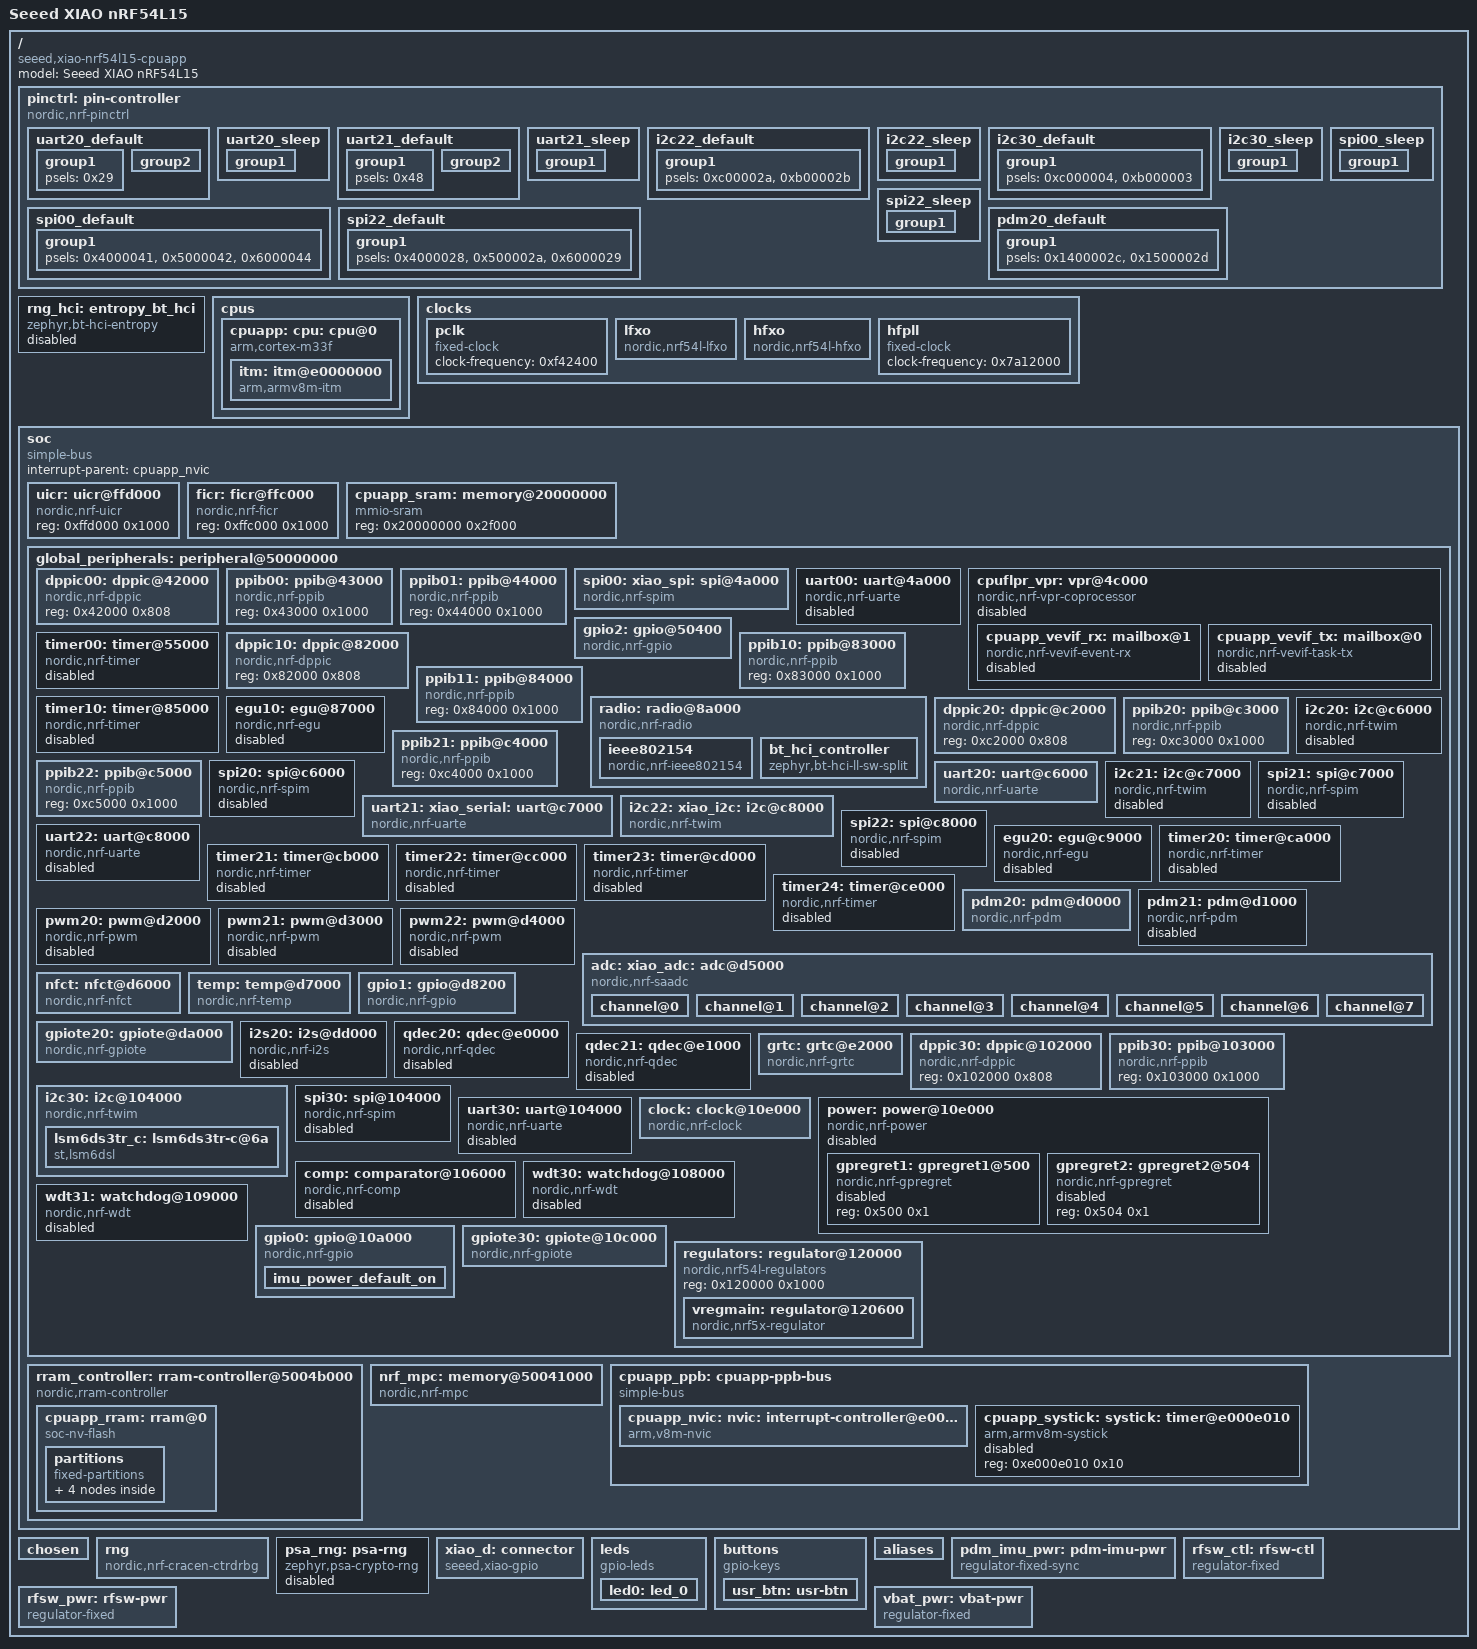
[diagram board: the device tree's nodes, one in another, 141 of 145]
/dts-v1/;

/* node '/' defined in framework-zephyr\dts\vendor\nordic\nrf_common.dtsi:24 */
/ {
	#address-cells = < 0x1 >;                  /* in framework-zephyr\dts\vendor\nordic\nrf54l_05_10_15.dtsi:19 */
	#size-cells = < 0x1 >;                     /* in framework-zephyr\dts\vendor\nordic\nrf54l_05_10_15.dtsi:20 */
	model = "Seeed XIAO nRF54L15";             /* in ..\platforms\Seeed Studio\zephyr\boards\arm\xiao_nrf54l15\xiao_nrf54l15_nrf54l15_cpuapp.dts:12 */
	compatible = "seeed,xiao-nrf54l15-cpuapp"; /* in ..\platforms\Seeed Studio\zephyr\boards\arm\xiao_nrf54l15\xiao_nrf54l15_nrf54l15_cpuapp.dts:13 */

	/* node '/pin-controller' defined in framework-zephyr\dts\vendor\nordic\nrf_common.dtsi:25 */
	pinctrl: pin-controller {
		compatible = "nordic,nrf-pinctrl"; /* in framework-zephyr\dts\vendor\nordic\nrf_common.dtsi:30 */

		/* node '/pin-controller/uart20_default' defined in ..\platforms\Seeed Studio\zephyr\boards\arm\xiao_nrf54l15\xiao_nrf54l15-pinctrl.dtsi:6 */
		uart20_default: uart20_default {
			phandle = < 0x6 >; /* in ..\platforms\Seeed Studio\zephyr\boards\arm\xiao_nrf54l15\xiao_nrf54l15_common.dtsi:39 */

			/* node '/pin-controller/uart20_default/group1' defined in ..\platforms\Seeed Studio\zephyr\boards\arm\xiao_nrf54l15\xiao_nrf54l15-pinctrl.dtsi:7 */
			group1 {
				psels = < 0x29 >; /* in ..\platforms\Seeed Studio\zephyr\boards\arm\xiao_nrf54l15\xiao_nrf54l15-pinctrl.dtsi:8 */
			};

			/* node '/pin-controller/uart20_default/group2' defined in ..\platforms\Seeed Studio\zephyr\boards\arm\xiao_nrf54l15\xiao_nrf54l15-pinctrl.dtsi:11 */
			group2 {
				psels = < 0x1000028 >; /* in ..\platforms\Seeed Studio\zephyr\boards\arm\xiao_nrf54l15\xiao_nrf54l15-pinctrl.dtsi:12 */
				bias-pull-up;          /* in ..\platforms\Seeed Studio\zephyr\boards\arm\xiao_nrf54l15\xiao_nrf54l15-pinctrl.dtsi:13 */
			};
		};

		/* node '/pin-controller/uart20_sleep' defined in ..\platforms\Seeed Studio\zephyr\boards\arm\xiao_nrf54l15\xiao_nrf54l15-pinctrl.dtsi:17 */
		uart20_sleep: uart20_sleep {
			phandle = < 0x7 >; /* in ..\platforms\Seeed Studio\zephyr\boards\arm\xiao_nrf54l15\xiao_nrf54l15_common.dtsi:40 */

			/* node '/pin-controller/uart20_sleep/group1' defined in ..\platforms\Seeed Studio\zephyr\boards\arm\xiao_nrf54l15\xiao_nrf54l15-pinctrl.dtsi:18 */
			group1 {
				psels = < 0x29 >,
				        < 0x1000028 >; /* in ..\platforms\Seeed Studio\zephyr\boards\arm\xiao_nrf54l15\xiao_nrf54l15-pinctrl.dtsi:19 */
				low-power-enable;      /* in ..\platforms\Seeed Studio\zephyr\boards\arm\xiao_nrf54l15\xiao_nrf54l15-pinctrl.dtsi:21 */
			};
		};

		/* node '/pin-controller/uart21_default' defined in ..\platforms\Seeed Studio\zephyr\boards\arm\xiao_nrf54l15\xiao_nrf54l15-pinctrl.dtsi:25 */
		uart21_default: uart21_default {
			phandle = < 0x8 >; /* in ..\platforms\Seeed Studio\zephyr\boards\arm\xiao_nrf54l15\xiao_nrf54l15_common.dtsi:46 */

			/* node '/pin-controller/uart21_default/group1' defined in ..\platforms\Seeed Studio\zephyr\boards\arm\xiao_nrf54l15\xiao_nrf54l15-pinctrl.dtsi:26 */
			group1 {
				psels = < 0x48 >; /* in ..\platforms\Seeed Studio\zephyr\boards\arm\xiao_nrf54l15\xiao_nrf54l15-pinctrl.dtsi:27 */
			};

			/* node '/pin-controller/uart21_default/group2' defined in ..\platforms\Seeed Studio\zephyr\boards\arm\xiao_nrf54l15\xiao_nrf54l15-pinctrl.dtsi:30 */
			group2 {
				psels = < 0x1000047 >; /* in ..\platforms\Seeed Studio\zephyr\boards\arm\xiao_nrf54l15\xiao_nrf54l15-pinctrl.dtsi:31 */
				bias-pull-up;          /* in ..\platforms\Seeed Studio\zephyr\boards\arm\xiao_nrf54l15\xiao_nrf54l15-pinctrl.dtsi:32 */
			};
		};

		/* node '/pin-controller/uart21_sleep' defined in ..\platforms\Seeed Studio\zephyr\boards\arm\xiao_nrf54l15\xiao_nrf54l15-pinctrl.dtsi:36 */
		uart21_sleep: uart21_sleep {
			phandle = < 0x9 >; /* in ..\platforms\Seeed Studio\zephyr\boards\arm\xiao_nrf54l15\xiao_nrf54l15_common.dtsi:47 */

			/* node '/pin-controller/uart21_sleep/group1' defined in ..\platforms\Seeed Studio\zephyr\boards\arm\xiao_nrf54l15\xiao_nrf54l15-pinctrl.dtsi:37 */
			group1 {
				psels = < 0x48 >,
				        < 0x1000047 >; /* in ..\platforms\Seeed Studio\zephyr\boards\arm\xiao_nrf54l15\xiao_nrf54l15-pinctrl.dtsi:38 */
				low-power-enable;      /* in ..\platforms\Seeed Studio\zephyr\boards\arm\xiao_nrf54l15\xiao_nrf54l15-pinctrl.dtsi:40 */
			};
		};

		/* node '/pin-controller/i2c22_default' defined in ..\platforms\Seeed Studio\zephyr\boards\arm\xiao_nrf54l15\xiao_nrf54l15-pinctrl.dtsi:44 */
		i2c22_default: i2c22_default {
			phandle = < 0xa >; /* in ..\platforms\Seeed Studio\zephyr\boards\arm\xiao_nrf54l15\xiao_nrf54l15_common.dtsi:52 */

			/* node '/pin-controller/i2c22_default/group1' defined in ..\platforms\Seeed Studio\zephyr\boards\arm\xiao_nrf54l15\xiao_nrf54l15-pinctrl.dtsi:45 */
			group1 {
				psels = < 0xc00002a >,
				        < 0xb00002b >; /* in ..\platforms\Seeed Studio\zephyr\boards\arm\xiao_nrf54l15\xiao_nrf54l15-pinctrl.dtsi:46 */
			};
		};

		/* node '/pin-controller/i2c22_sleep' defined in ..\platforms\Seeed Studio\zephyr\boards\arm\xiao_nrf54l15\xiao_nrf54l15-pinctrl.dtsi:51 */
		i2c22_sleep: i2c22_sleep {
			phandle = < 0xb >; /* in ..\platforms\Seeed Studio\zephyr\boards\arm\xiao_nrf54l15\xiao_nrf54l15_common.dtsi:53 */

			/* node '/pin-controller/i2c22_sleep/group1' defined in ..\platforms\Seeed Studio\zephyr\boards\arm\xiao_nrf54l15\xiao_nrf54l15-pinctrl.dtsi:52 */
			group1 {
				psels = < 0xc00002a >,
				        < 0xb00002b >; /* in ..\platforms\Seeed Studio\zephyr\boards\arm\xiao_nrf54l15\xiao_nrf54l15-pinctrl.dtsi:53 */
				low-power-enable;      /* in ..\platforms\Seeed Studio\zephyr\boards\arm\xiao_nrf54l15\xiao_nrf54l15-pinctrl.dtsi:55 */
			};
		};

		/* node '/pin-controller/i2c30_default' defined in ..\platforms\Seeed Studio\zephyr\boards\arm\xiao_nrf54l15\xiao_nrf54l15-pinctrl.dtsi:59 */
		i2c30_default: i2c30_default {
			phandle = < 0x12 >; /* in ..\platforms\Seeed Studio\zephyr\boards\arm\xiao_nrf54l15\xiao_nrf54l15_common.dtsi:59 */

			/* node '/pin-controller/i2c30_default/group1' defined in ..\platforms\Seeed Studio\zephyr\boards\arm\xiao_nrf54l15\xiao_nrf54l15-pinctrl.dtsi:60 */
			group1 {
				psels = < 0xc000004 >,
				        < 0xb000003 >; /* in ..\platforms\Seeed Studio\zephyr\boards\arm\xiao_nrf54l15\xiao_nrf54l15-pinctrl.dtsi:61 */
			};
		};

		/* node '/pin-controller/i2c30_sleep' defined in ..\platforms\Seeed Studio\zephyr\boards\arm\xiao_nrf54l15\xiao_nrf54l15-pinctrl.dtsi:66 */
		i2c30_sleep: i2c30_sleep {
			phandle = < 0x13 >; /* in ..\platforms\Seeed Studio\zephyr\boards\arm\xiao_nrf54l15\xiao_nrf54l15_common.dtsi:60 */

			/* node '/pin-controller/i2c30_sleep/group1' defined in ..\platforms\Seeed Studio\zephyr\boards\arm\xiao_nrf54l15\xiao_nrf54l15-pinctrl.dtsi:67 */
			group1 {
				psels = < 0xc000004 >,
				        < 0xb000003 >; /* in ..\platforms\Seeed Studio\zephyr\boards\arm\xiao_nrf54l15\xiao_nrf54l15-pinctrl.dtsi:68 */
				low-power-enable;      /* in ..\platforms\Seeed Studio\zephyr\boards\arm\xiao_nrf54l15\xiao_nrf54l15-pinctrl.dtsi:70 */
			};
		};

		/* node '/pin-controller/spi00_default' defined in ..\platforms\Seeed Studio\zephyr\boards\arm\xiao_nrf54l15\xiao_nrf54l15-pinctrl.dtsi:74 */
		spi00_default: spi00_default {
			phandle = < 0x3 >; /* in ..\platforms\Seeed Studio\zephyr\boards\arm\xiao_nrf54l15\xiao_nrf54l15_common.dtsi:66 */

			/* node '/pin-controller/spi00_default/group1' defined in ..\platforms\Seeed Studio\zephyr\boards\arm\xiao_nrf54l15\xiao_nrf54l15-pinctrl.dtsi:75 */
			group1 {
				psels = < 0x4000041 >,
				        < 0x5000042 >,
				        < 0x6000044 >; /* in ..\platforms\Seeed Studio\zephyr\boards\arm\xiao_nrf54l15\xiao_nrf54l15-pinctrl.dtsi:76 */
			};
		};

		/* node '/pin-controller/spi00_sleep' defined in ..\platforms\Seeed Studio\zephyr\boards\arm\xiao_nrf54l15\xiao_nrf54l15-pinctrl.dtsi:82 */
		spi00_sleep: spi00_sleep {
			phandle = < 0x4 >; /* in ..\platforms\Seeed Studio\zephyr\boards\arm\xiao_nrf54l15\xiao_nrf54l15_common.dtsi:67 */

			/* node '/pin-controller/spi00_sleep/group1' defined in ..\platforms\Seeed Studio\zephyr\boards\arm\xiao_nrf54l15\xiao_nrf54l15-pinctrl.dtsi:83 */
			group1 {
				psels = < 0x4000041 >,
				        < 0x5000042 >,
				        < 0x6000044 >; /* in ..\platforms\Seeed Studio\zephyr\boards\arm\xiao_nrf54l15\xiao_nrf54l15-pinctrl.dtsi:84 */
				low-power-enable;      /* in ..\platforms\Seeed Studio\zephyr\boards\arm\xiao_nrf54l15\xiao_nrf54l15-pinctrl.dtsi:87 */
			};
		};

		/* node '/pin-controller/spi22_default' defined in ..\platforms\Seeed Studio\zephyr\boards\arm\xiao_nrf54l15\xiao_nrf54l15-pinctrl.dtsi:91 */
		spi22_default: spi22_default {
			phandle = < 0xc >; /* in ..\platforms\Seeed Studio\zephyr\boards\arm\xiao_nrf54l15\xiao_nrf54l15_common.dtsi:72 */

			/* node '/pin-controller/spi22_default/group1' defined in ..\platforms\Seeed Studio\zephyr\boards\arm\xiao_nrf54l15\xiao_nrf54l15-pinctrl.dtsi:92 */
			group1 {
				psels = < 0x4000028 >,
				        < 0x500002a >,
				        < 0x6000029 >; /* in ..\platforms\Seeed Studio\zephyr\boards\arm\xiao_nrf54l15\xiao_nrf54l15-pinctrl.dtsi:93 */
			};
		};

		/* node '/pin-controller/spi22_sleep' defined in ..\platforms\Seeed Studio\zephyr\boards\arm\xiao_nrf54l15\xiao_nrf54l15-pinctrl.dtsi:99 */
		spi22_sleep: spi22_sleep {
			phandle = < 0xd >; /* in ..\platforms\Seeed Studio\zephyr\boards\arm\xiao_nrf54l15\xiao_nrf54l15_common.dtsi:73 */

			/* node '/pin-controller/spi22_sleep/group1' defined in ..\platforms\Seeed Studio\zephyr\boards\arm\xiao_nrf54l15\xiao_nrf54l15-pinctrl.dtsi:100 */
			group1 {
				psels = < 0x4000028 >,
				        < 0x500002a >,
				        < 0x6000029 >; /* in ..\platforms\Seeed Studio\zephyr\boards\arm\xiao_nrf54l15\xiao_nrf54l15-pinctrl.dtsi:101 */
				low-power-enable;      /* in ..\platforms\Seeed Studio\zephyr\boards\arm\xiao_nrf54l15\xiao_nrf54l15-pinctrl.dtsi:104 */
			};
		};

		/* node '/pin-controller/pdm20_default' defined in ..\platforms\Seeed Studio\zephyr\boards\arm\xiao_nrf54l15\xiao_nrf54l15-pinctrl.dtsi:108 */
		pdm20_default: pdm20_default {
			phandle = < 0xe >; /* in ..\platforms\Seeed Studio\zephyr\boards\arm\xiao_nrf54l15\xiao_nrf54l15_common.dtsi:78 */

			/* node '/pin-controller/pdm20_default/group1' defined in ..\platforms\Seeed Studio\zephyr\boards\arm\xiao_nrf54l15\xiao_nrf54l15-pinctrl.dtsi:109 */
			group1 {
				psels = < 0x1400002c >,
				        < 0x1500002d >; /* in ..\platforms\Seeed Studio\zephyr\boards\arm\xiao_nrf54l15\xiao_nrf54l15-pinctrl.dtsi:110 */
			};
		};
	};

	/* node '/entropy_bt_hci' defined in framework-zephyr\dts\vendor\nordic\nrf_common.dtsi:33 */
	rng_hci: entropy_bt_hci {
		compatible = "zephyr,bt-hci-entropy"; /* in framework-zephyr\dts\vendor\nordic\nrf_common.dtsi:34 */
		status = "disabled";                  /* in framework-zephyr\dts\vendor\nordic\nrf_common.dtsi:35 */
	};

	/* node '/cpus' defined in framework-zephyr\dts\vendor\nordic\nrf54l_05_10_15.dtsi:22 */
	cpus {
		#address-cells = < 0x1 >; /* in framework-zephyr\dts\vendor\nordic\nrf54l_05_10_15.dtsi:23 */
		#size-cells = < 0x0 >;    /* in framework-zephyr\dts\vendor\nordic\nrf54l_05_10_15.dtsi:24 */

		/* node '/cpus/cpu@0' defined in framework-zephyr\dts\vendor\nordic\nrf54l_05_10_15.dtsi:26 */
		cpuapp: cpu: cpu@0 {
			compatible = "arm,cortex-m33f"; /* in framework-zephyr\dts\vendor\nordic\nrf54l_05_10_15.dtsi:27 */
			reg = < 0x0 >;                  /* in framework-zephyr\dts\vendor\nordic\nrf54l_05_10_15.dtsi:28 */
			device_type = "cpu";            /* in framework-zephyr\dts\vendor\nordic\nrf54l_05_10_15.dtsi:29 */
			clocks = < &hfpll >;            /* in framework-zephyr\dts\vendor\nordic\nrf54l_05_10_15.dtsi:30 */
			#address-cells = < 0x1 >;       /* in framework-zephyr\dts\vendor\nordic\nrf54l_05_10_15.dtsi:31 */
			#size-cells = < 0x1 >;          /* in framework-zephyr\dts\vendor\nordic\nrf54l_05_10_15.dtsi:32 */

			/* node '/cpus/cpu@0/itm@e0000000' defined in framework-zephyr\dts\vendor\nordic\nrf54l_05_10_15.dtsi:34 */
			itm: itm@e0000000 {
				compatible = "arm,armv8m-itm";     /* in framework-zephyr\dts\vendor\nordic\nrf54l_05_10_15.dtsi:35 */
				reg = < 0xe0000000 0x1000 >;       /* in framework-zephyr\dts\vendor\nordic\nrf54l_05_10_15.dtsi:36 */
				swo-ref-frequency = < 0x7a12000 >; /* in framework-zephyr\dts\vendor\nordic\nrf54l_05_10_15.dtsi:37 */
			};
		};
	};

	/* node '/clocks' defined in framework-zephyr\dts\vendor\nordic\nrf54l_05_10_15.dtsi:51 */
	clocks {

		/* node '/clocks/pclk' defined in framework-zephyr\dts\vendor\nordic\nrf54l_05_10_15.dtsi:52 */
		pclk: pclk {
			compatible = "fixed-clock";     /* in framework-zephyr\dts\vendor\nordic\nrf54l_05_10_15.dtsi:53 */
			#clock-cells = < 0x0 >;         /* in framework-zephyr\dts\vendor\nordic\nrf54l_05_10_15.dtsi:54 */
			clock-frequency = < 0xf42400 >; /* in framework-zephyr\dts\vendor\nordic\nrf54l_05_10_15.dtsi:55 */
			phandle = < 0x11 >;             /* in framework-zephyr\dts\vendor\nordic\nrf54l_05_10_15.dtsi:569 */
		};

		/* node '/clocks/lfxo' defined in framework-zephyr\dts\vendor\nordic\nrf54l_05_10_15.dtsi:58 */
		lfxo: lfxo {
			compatible = "nordic,nrf54l-lfxo";        /* in framework-zephyr\dts\vendor\nordic\nrf54l_05_10_15.dtsi:59 */
			#clock-cells = < 0x0 >;                   /* in framework-zephyr\dts\vendor\nordic\nrf54l_05_10_15.dtsi:60 */
			clock-frequency = < 0x8000 >;             /* in framework-zephyr\dts\vendor\nordic\nrf54l_05_10_15.dtsi:61 */
			load-capacitors = "internal";             /* in ..\platforms\Seeed Studio\zephyr\boards\arm\xiao_nrf54l15\xiao_nrf54l15_nrf54l15_cpuapp.dts:146 */
			load-capacitance-femtofarad = < 0x3e80 >; /* in ..\platforms\Seeed Studio\zephyr\boards\arm\xiao_nrf54l15\xiao_nrf54l15_nrf54l15_cpuapp.dts:147 */
			status = "okay";                          /* in ..\platforms\Seeed Studio\zephyr\boards\arm\xiao_nrf54l15\xiao_nrf54l15_nrf54l15_cpuapp.dts:148 */
			phandle = < 0x10 >;                       /* in framework-zephyr\dts\vendor\nordic\nrf54l_05_10_15.dtsi:569 */
		};

		/* node '/clocks/hfxo' defined in framework-zephyr\dts\vendor\nordic\nrf54l_05_10_15.dtsi:64 */
		hfxo: hfxo {
			compatible = "nordic,nrf54l-hfxo";        /* in framework-zephyr\dts\vendor\nordic\nrf54l_05_10_15.dtsi:65 */
			#clock-cells = < 0x0 >;                   /* in framework-zephyr\dts\vendor\nordic\nrf54l_05_10_15.dtsi:66 */
			clock-frequency = < 0x1e84800 >;          /* in framework-zephyr\dts\vendor\nordic\nrf54l_05_10_15.dtsi:67 */
			startup-time-us = < 0x672 >;              /* in framework-zephyr\dts\vendor\nordic\nrf54l_05_10_15.dtsi:68 */
			load-capacitors = "internal";             /* in ..\platforms\Seeed Studio\zephyr\boards\arm\xiao_nrf54l15\xiao_nrf54l15_nrf54l15_cpuapp.dts:152 */
			load-capacitance-femtofarad = < 0x3e80 >; /* in ..\platforms\Seeed Studio\zephyr\boards\arm\xiao_nrf54l15\xiao_nrf54l15_nrf54l15_cpuapp.dts:153 */
			status = "okay";                          /* in ..\platforms\Seeed Studio\zephyr\boards\arm\xiao_nrf54l15\xiao_nrf54l15_nrf54l15_cpuapp.dts:154 */
			phandle = < 0x5 >;                        /* in framework-zephyr\dts\vendor\nordic\nrf54l_05_10_15.dtsi:226 */
		};

		/* node '/clocks/hfpll' defined in framework-zephyr\dts\vendor\nordic\nrf54l_05_10_15.dtsi:71 */
		hfpll: hfpll {
			compatible = "fixed-clock";      /* in framework-zephyr\dts\vendor\nordic\nrf54l_05_10_15.dtsi:72 */
			#clock-cells = < 0x0 >;          /* in framework-zephyr\dts\vendor\nordic\nrf54l_05_10_15.dtsi:73 */
			clock-frequency = < 0x7a12000 >; /* in framework-zephyr\dts\vendor\nordic\nrf54l_05_10_15.dtsi:74 */
			phandle = < 0x1 >;               /* in framework-zephyr\dts\vendor\nordic\nrf54l_05_10_15.dtsi:30 */
		};
	};

	/* node '/soc' defined in framework-zephyr\dts\vendor\nordic\nrf54l_05_10_15.dtsi:78 */
	soc {
		#address-cells = < 0x1 >;            /* in framework-zephyr\dts\vendor\nordic\nrf54l_05_10_15.dtsi:79 */
		#size-cells = < 0x1 >;               /* in framework-zephyr\dts\vendor\nordic\nrf54l_05_10_15.dtsi:80 */
		compatible = "simple-bus";           /* in framework-zephyr\dts\arm\nordic\nrf54l_05_10_15_cpuapp.dtsi:23 */
		interrupt-parent = < &cpuapp_nvic >; /* in framework-zephyr\dts\arm\nordic\nrf54l_05_10_15_cpuapp.dtsi:24 */
		ranges;                              /* in framework-zephyr\dts\arm\nordic\nrf54l_05_10_15_cpuapp.dtsi:25 */

		/* node '/soc/uicr@ffd000' defined in framework-zephyr\dts\vendor\nordic\nrf54l_05_10_15.dtsi:85 */
		uicr: uicr@ffd000 {
			compatible = "nordic,nrf-uicr"; /* in framework-zephyr\dts\vendor\nordic\nrf54l_05_10_15.dtsi:86 */
			reg = < 0xffd000 0x1000 >;      /* in framework-zephyr\dts\vendor\nordic\nrf54l_05_10_15.dtsi:87 */
		};

		/* node '/soc/ficr@ffc000' defined in framework-zephyr\dts\vendor\nordic\nrf54l_05_10_15.dtsi:90 */
		ficr: ficr@ffc000 {
			compatible = "nordic,nrf-ficr"; /* in framework-zephyr\dts\vendor\nordic\nrf54l_05_10_15.dtsi:91 */
			reg = < 0xffc000 0x1000 >;      /* in framework-zephyr\dts\vendor\nordic\nrf54l_05_10_15.dtsi:92 */
			#nordic,ficr-cells = < 0x1 >;   /* in framework-zephyr\dts\vendor\nordic\nrf54l_05_10_15.dtsi:93 */
		};

		/* node '/soc/memory@20000000' defined in framework-zephyr\dts\vendor\nordic\nrf54l_05_10_15.dtsi:96 */
		cpuapp_sram: memory@20000000 {
			compatible = "mmio-sram";            /* in framework-zephyr\dts\vendor\nordic\nrf54l_05_10_15.dtsi:97 */
			#address-cells = < 0x1 >;            /* in framework-zephyr\dts\vendor\nordic\nrf54l_05_10_15.dtsi:98 */
			#size-cells = < 0x1 >;               /* in framework-zephyr\dts\vendor\nordic\nrf54l_05_10_15.dtsi:99 */
			reg = < 0x20000000 0x2f000 >;        /* in framework-zephyr\dts\vendor\nordic\nrf54l15.dtsi:10 */
			ranges = < 0x0 0x20000000 0x2f000 >; /* in framework-zephyr\dts\vendor\nordic\nrf54l15.dtsi:11 */
			status = "okay";                     /* in ..\platforms\Seeed Studio\zephyr\boards\arm\xiao_nrf54l15\xiao_nrf54l15_nrf54l15_cpuapp.dts:61 */
		};

		/* node '/soc/peripheral@50000000' defined in framework-zephyr\dts\vendor\nordic\nrf54l_05_10_15.dtsi:108 */
		global_peripherals: peripheral@50000000 {
			#address-cells = < 0x1 >;               /* in framework-zephyr\dts\vendor\nordic\nrf54l_05_10_15.dtsi:109 */
			#size-cells = < 0x1 >;                  /* in framework-zephyr\dts\vendor\nordic\nrf54l_05_10_15.dtsi:110 */
			ranges = < 0x0 0x50000000 0x10000000 >; /* in framework-zephyr\dts\vendor\nordic\nrf54l_05_10_15.dtsi:111 */

			/* node '/soc/peripheral@50000000/dppic@42000' defined in framework-zephyr\dts\vendor\nordic\nrf54l_05_10_15.dtsi:114 */
			dppic00: dppic@42000 {
				compatible = "nordic,nrf-dppic"; /* in framework-zephyr\dts\vendor\nordic\nrf54l_05_10_15.dtsi:115 */
				reg = < 0x42000 0x808 >;         /* in framework-zephyr\dts\vendor\nordic\nrf54l_05_10_15.dtsi:116 */
				status = "okay";                 /* in framework-zephyr\dts\arm\nordic\nrf54l_05_10_15_cpuapp.dtsi:95 */
			};

			/* node '/soc/peripheral@50000000/ppib@43000' defined in framework-zephyr\dts\vendor\nordic\nrf54l_05_10_15.dtsi:120 */
			ppib00: ppib@43000 {
				compatible = "nordic,nrf-ppib"; /* in framework-zephyr\dts\vendor\nordic\nrf54l_05_10_15.dtsi:121 */
				reg = < 0x43000 0x1000 >;       /* in framework-zephyr\dts\vendor\nordic\nrf54l_05_10_15.dtsi:122 */
				status = "okay";                /* in framework-zephyr\dts\arm\nordic\nrf54l_05_10_15_cpuapp.dtsi:111 */
			};

			/* node '/soc/peripheral@50000000/ppib@44000' defined in framework-zephyr\dts\vendor\nordic\nrf54l_05_10_15.dtsi:126 */
			ppib01: ppib@44000 {
				compatible = "nordic,nrf-ppib"; /* in framework-zephyr\dts\vendor\nordic\nrf54l_05_10_15.dtsi:127 */
				reg = < 0x44000 0x1000 >;       /* in framework-zephyr\dts\vendor\nordic\nrf54l_05_10_15.dtsi:128 */
				status = "okay";                /* in framework-zephyr\dts\arm\nordic\nrf54l_05_10_15_cpuapp.dtsi:115 */
			};

			/* node '/soc/peripheral@50000000/spi@4a000' defined in framework-zephyr\dts\vendor\nordic\nrf54l_05_10_15.dtsi:132 */
			spi00: xiao_spi: spi@4a000 {
				compatible = "nordic,nrf-spim"; /* in framework-zephyr\dts\vendor\nordic\nrf54l_05_10_15.dtsi:139 */
				#address-cells = < 0x1 >;       /* in framework-zephyr\dts\vendor\nordic\nrf54l_05_10_15.dtsi:140 */
				#size-cells = < 0x0 >;          /* in framework-zephyr\dts\vendor\nordic\nrf54l_05_10_15.dtsi:141 */
				reg = < 0x4a000 0x1000 >;       /* in framework-zephyr\dts\vendor\nordic\nrf54l_05_10_15.dtsi:142 */
				interrupts = < 0x4a 0x1 >;      /* in framework-zephyr\dts\vendor\nordic\nrf54l_05_10_15.dtsi:143 */
				max-frequency = < 0x1e84800 >;  /* in framework-zephyr\dts\vendor\nordic\nrf54l_05_10_15.dtsi:144 */
				easydma-maxcnt-bits = < 0x10 >; /* in framework-zephyr\dts\vendor\nordic\nrf54l_05_10_15.dtsi:145 */
				rx-delay-supported;             /* in framework-zephyr\dts\vendor\nordic\nrf54l_05_10_15.dtsi:146 */
				rx-delay = < 0x1 >;             /* in framework-zephyr\dts\vendor\nordic\nrf54l_05_10_15.dtsi:147 */
				pinctrl-0 = < &spi00_default >; /* in ..\platforms\Seeed Studio\zephyr\boards\arm\xiao_nrf54l15\xiao_nrf54l15_common.dtsi:66 */
				pinctrl-1 = < &spi00_sleep >;   /* in ..\platforms\Seeed Studio\zephyr\boards\arm\xiao_nrf54l15\xiao_nrf54l15_common.dtsi:67 */
				pinctrl-names = "default",
				                "sleep";        /* in ..\platforms\Seeed Studio\zephyr\boards\arm\xiao_nrf54l15\xiao_nrf54l15_common.dtsi:68 */
				status = "okay";                /* in ..\platforms\Seeed Studio\zephyr\boards\arm\xiao_nrf54l15\xiao_nrf54l15_nrf54l15_cpuapp.dts:99 */
				clocks = < &hfpll >;            /* in H:/nrf54l15/spi/zephyr/xiao_nrf54l15_nrf54l15_cpuapp.overlay:14 */
			};

			/* node '/soc/peripheral@50000000/uart@4a000' defined in framework-zephyr\dts\vendor\nordic\nrf54l_05_10_15.dtsi:151 */
			uart00: uart@4a000 {
				compatible = "nordic,nrf-uarte"; /* in framework-zephyr\dts\vendor\nordic\nrf54l_05_10_15.dtsi:152 */
				reg = < 0x4a000 0x1000 >;        /* in framework-zephyr\dts\vendor\nordic\nrf54l_05_10_15.dtsi:153 */
				interrupts = < 0x4a 0x1 >;       /* in framework-zephyr\dts\vendor\nordic\nrf54l_05_10_15.dtsi:154 */
				clocks = < &hfpll >;             /* in framework-zephyr\dts\vendor\nordic\nrf54l_05_10_15.dtsi:155 */
				status = "disabled";             /* in framework-zephyr\dts\vendor\nordic\nrf54l_05_10_15.dtsi:156 */
				endtx-stoptx-supported;          /* in framework-zephyr\dts\vendor\nordic\nrf54l_05_10_15.dtsi:157 */
				frame-timeout-supported;         /* in framework-zephyr\dts\vendor\nordic\nrf54l_05_10_15.dtsi:158 */
			};

			/* node '/soc/peripheral@50000000/vpr@4c000' defined in framework-zephyr\dts\vendor\nordic\nrf54l_05_10_15.dtsi:161 */
			cpuflpr_vpr: vpr@4c000 {
				compatible = "nordic,nrf-vpr-coprocessor"; /* in framework-zephyr\dts\vendor\nordic\nrf54l_05_10_15.dtsi:162 */
				reg = < 0x4c000 0x1000 >;                  /* in framework-zephyr\dts\vendor\nordic\nrf54l_05_10_15.dtsi:163 */
				ranges = < 0x0 0x4c000 0x1000 >;           /* in framework-zephyr\dts\vendor\nordic\nrf54l_05_10_15.dtsi:164 */
				#address-cells = < 0x1 >;                  /* in framework-zephyr\dts\vendor\nordic\nrf54l_05_10_15.dtsi:165 */
				#size-cells = < 0x1 >;                     /* in framework-zephyr\dts\vendor\nordic\nrf54l_05_10_15.dtsi:166 */
				status = "disabled";                       /* in framework-zephyr\dts\vendor\nordic\nrf54l_05_10_15.dtsi:167 */
				enable-secure;                             /* in framework-zephyr\dts\vendor\nordic\nrf54l_05_10_15.dtsi:168 */

				/* node '/soc/peripheral@50000000/vpr@4c000/mailbox@1' defined in framework-zephyr\dts\arm\nordic\nrf54l_05_10_15_cpuapp.dtsi:44 */
				cpuapp_vevif_rx: mailbox@1 {
					compatible = "nordic,nrf-vevif-event-rx"; /* in framework-zephyr\dts\arm\nordic\nrf54l_05_10_15_cpuapp.dtsi:45 */
					reg = < 0x1 0x1000 >;                     /* in framework-zephyr\dts\arm\nordic\nrf54l_05_10_15_cpuapp.dtsi:46 */
					status = "disabled";                      /* in framework-zephyr\dts\arm\nordic\nrf54l_05_10_15_cpuapp.dtsi:47 */
					interrupts = < 0x4c 0x1 >;                /* in framework-zephyr\dts\arm\nordic\nrf54l_05_10_15_cpuapp.dtsi:48 */
					#mbox-cells = < 0x1 >;                    /* in framework-zephyr\dts\arm\nordic\nrf54l_05_10_15_cpuapp.dtsi:49 */
					nordic,events = < 0x1 >;                  /* in framework-zephyr\dts\arm\nordic\nrf54l_05_10_15_cpuapp.dtsi:50 */
					nordic,events-mask = < 0x100000 >;        /* in framework-zephyr\dts\arm\nordic\nrf54l_05_10_15_cpuapp.dtsi:51 */
				};

				/* node '/soc/peripheral@50000000/vpr@4c000/mailbox@0' defined in framework-zephyr\dts\arm\nordic\nrf54l_05_10_15_cpuapp.dtsi:54 */
				cpuapp_vevif_tx: mailbox@0 {
					compatible = "nordic,nrf-vevif-task-tx"; /* in framework-zephyr\dts\arm\nordic\nrf54l_05_10_15_cpuapp.dtsi:55 */
					reg = < 0x0 0x1000 >;                    /* in framework-zephyr\dts\arm\nordic\nrf54l_05_10_15_cpuapp.dtsi:56 */
					#mbox-cells = < 0x1 >;                   /* in framework-zephyr\dts\arm\nordic\nrf54l_05_10_15_cpuapp.dtsi:57 */
					nordic,tasks = < 0x7 >;                  /* in framework-zephyr\dts\arm\nordic\nrf54l_05_10_15_cpuapp.dtsi:58 */
					nordic,tasks-mask = < 0x7f0000 >;        /* in framework-zephyr\dts\arm\nordic\nrf54l_05_10_15_cpuapp.dtsi:59 */
					status = "disabled";                     /* in framework-zephyr\dts\arm\nordic\nrf54l_05_10_15_cpuapp.dtsi:60 */
				};
			};

			/* node '/soc/peripheral@50000000/gpio@50400' defined in framework-zephyr\dts\vendor\nordic\nrf54l_05_10_15.dtsi:180 */
			gpio2: gpio@50400 {
				compatible = "nordic,nrf-gpio"; /* in framework-zephyr\dts\vendor\nordic\nrf54l_05_10_15.dtsi:181 */
				gpio-controller;                /* in framework-zephyr\dts\vendor\nordic\nrf54l_05_10_15.dtsi:182 */
				reg = < 0x50400 0x300 >;        /* in framework-zephyr\dts\vendor\nordic\nrf54l_05_10_15.dtsi:183 */
				#gpio-cells = < 0x2 >;          /* in framework-zephyr\dts\vendor\nordic\nrf54l_05_10_15.dtsi:184 */
				ngpios = < 0xb >;               /* in framework-zephyr\dts\vendor\nordic\nrf54l_05_10_15.dtsi:185 */
				port = < 0x2 >;                 /* in framework-zephyr\dts\vendor\nordic\nrf54l_05_10_15.dtsi:187 */
				status = "okay";                /* in ..\platforms\Seeed Studio\zephyr\boards\arm\xiao_nrf54l15\xiao_nrf54l15_nrf54l15_cpuapp.dts:125 */
				phandle = < 0x17 >;             /* in ..\platforms\Seeed Studio\zephyr\boards\arm\xiao_nrf54l15\seeed_xiao_connector.dtsi:11 */
			};

			/* node '/soc/peripheral@50000000/timer@55000' defined in framework-zephyr\dts\vendor\nordic\nrf54l_05_10_15.dtsi:190 */
			timer00: timer@55000 {
				compatible = "nordic,nrf-timer"; /* in framework-zephyr\dts\vendor\nordic\nrf54l_05_10_15.dtsi:191 */
				status = "disabled";             /* in framework-zephyr\dts\vendor\nordic\nrf54l_05_10_15.dtsi:192 */
				reg = < 0x55000 0x1000 >;        /* in framework-zephyr\dts\vendor\nordic\nrf54l_05_10_15.dtsi:193 */
				cc-num = < 0x6 >;                /* in framework-zephyr\dts\vendor\nordic\nrf54l_05_10_15.dtsi:194 */
				max-bit-width = < 0x20 >;        /* in framework-zephyr\dts\vendor\nordic\nrf54l_05_10_15.dtsi:195 */
				interrupts = < 0x55 0x1 >;       /* in framework-zephyr\dts\vendor\nordic\nrf54l_05_10_15.dtsi:196 */
				clocks = < &hfpll >;             /* in framework-zephyr\dts\vendor\nordic\nrf54l_05_10_15.dtsi:197 */
				prescaler = < 0x0 >;             /* in framework-zephyr\dts\vendor\nordic\nrf54l_05_10_15.dtsi:198 */
			};

			/* node '/soc/peripheral@50000000/dppic@82000' defined in framework-zephyr\dts\vendor\nordic\nrf54l_05_10_15.dtsi:201 */
			dppic10: dppic@82000 {
				compatible = "nordic,nrf-dppic"; /* in framework-zephyr\dts\vendor\nordic\nrf54l_05_10_15.dtsi:202 */
				reg = < 0x82000 0x808 >;         /* in framework-zephyr\dts\vendor\nordic\nrf54l_05_10_15.dtsi:203 */
				status = "okay";                 /* in framework-zephyr\dts\arm\nordic\nrf54l_05_10_15_cpuapp.dtsi:99 */
			};

			/* node '/soc/peripheral@50000000/ppib@83000' defined in framework-zephyr\dts\vendor\nordic\nrf54l_05_10_15.dtsi:207 */
			ppib10: ppib@83000 {
				compatible = "nordic,nrf-ppib"; /* in framework-zephyr\dts\vendor\nordic\nrf54l_05_10_15.dtsi:208 */
				reg = < 0x83000 0x1000 >;       /* in framework-zephyr\dts\vendor\nordic\nrf54l_05_10_15.dtsi:209 */
				status = "okay";                /* in framework-zephyr\dts\arm\nordic\nrf54l_05_10_15_cpuapp.dtsi:119 */
			};

			/* node '/soc/peripheral@50000000/ppib@84000' defined in framework-zephyr\dts\vendor\nordic\nrf54l_05_10_15.dtsi:213 */
			ppib11: ppib@84000 {
				compatible = "nordic,nrf-ppib"; /* in framework-zephyr\dts\vendor\nordic\nrf54l_05_10_15.dtsi:214 */
				reg = < 0x84000 0x1000 >;       /* in framework-zephyr\dts\vendor\nordic\nrf54l_05_10_15.dtsi:215 */
				status = "okay";                /* in framework-zephyr\dts\arm\nordic\nrf54l_05_10_15_cpuapp.dtsi:123 */
			};

			/* node '/soc/peripheral@50000000/timer@85000' defined in framework-zephyr\dts\vendor\nordic\nrf54l_05_10_15.dtsi:219 */
			timer10: timer@85000 {
				compatible = "nordic,nrf-timer"; /* in framework-zephyr\dts\vendor\nordic\nrf54l_05_10_15.dtsi:220 */
				status = "disabled";             /* in framework-zephyr\dts\vendor\nordic\nrf54l_05_10_15.dtsi:221 */
				reg = < 0x85000 0x1000 >;        /* in framework-zephyr\dts\vendor\nordic\nrf54l_05_10_15.dtsi:222 */
				cc-num = < 0x8 >;                /* in framework-zephyr\dts\vendor\nordic\nrf54l_05_10_15.dtsi:223 */
				max-bit-width = < 0x20 >;        /* in framework-zephyr\dts\vendor\nordic\nrf54l_05_10_15.dtsi:224 */
				interrupts = < 0x85 0x1 >;       /* in framework-zephyr\dts\vendor\nordic\nrf54l_05_10_15.dtsi:225 */
				clocks = < &hfxo >;              /* in framework-zephyr\dts\vendor\nordic\nrf54l_05_10_15.dtsi:226 */
				prescaler = < 0x0 >;             /* in framework-zephyr\dts\vendor\nordic\nrf54l_05_10_15.dtsi:227 */
			};

			/* node '/soc/peripheral@50000000/egu@87000' defined in framework-zephyr\dts\vendor\nordic\nrf54l_05_10_15.dtsi:230 */
			egu10: egu@87000 {
				compatible = "nordic,nrf-egu"; /* in framework-zephyr\dts\vendor\nordic\nrf54l_05_10_15.dtsi:231 */
				reg = < 0x87000 0x1000 >;      /* in framework-zephyr\dts\vendor\nordic\nrf54l_05_10_15.dtsi:232 */
				interrupts = < 0x87 0x1 >;     /* in framework-zephyr\dts\vendor\nordic\nrf54l_05_10_15.dtsi:233 */
				status = "disabled";           /* in framework-zephyr\dts\vendor\nordic\nrf54l_05_10_15.dtsi:234 */
			};

			/* node '/soc/peripheral@50000000/radio@8a000' defined in framework-zephyr\dts\vendor\nordic\nrf54l_05_10_15.dtsi:237 */
			radio: radio@8a000 {
				compatible = "nordic,nrf-radio"; /* in framework-zephyr\dts\vendor\nordic\nrf54l_05_10_15.dtsi:238 */
				reg = < 0x8a000 0x1000 >;        /* in framework-zephyr\dts\vendor\nordic\nrf54l_05_10_15.dtsi:239 */
				interrupts = < 0x8a 0x1 >;       /* in framework-zephyr\dts\vendor\nordic\nrf54l_05_10_15.dtsi:240 */
				dfe-supported;                   /* in framework-zephyr\dts\vendor\nordic\nrf54l_05_10_15.dtsi:242 */
				ieee802154-supported;            /* in framework-zephyr\dts\vendor\nordic\nrf54l_05_10_15.dtsi:243 */
				ble-2mbps-supported;             /* in framework-zephyr\dts\vendor\nordic\nrf54l_05_10_15.dtsi:244 */
				ble-coded-phy-supported;         /* in framework-zephyr\dts\vendor\nordic\nrf54l_05_10_15.dtsi:245 */
				cs-supported;                    /* in framework-zephyr\dts\vendor\nordic\nrf54l_05_10_15.dtsi:246 */
				status = "okay";                 /* in ..\platforms\Seeed Studio\zephyr\boards\arm\xiao_nrf54l15\xiao_nrf54l15_nrf54l15_cpuapp.dts:167 */

				/* node '/soc/peripheral@50000000/radio@8a000/ieee802154' defined in framework-zephyr\dts\vendor\nordic\nrf54l_05_10_15.dtsi:248 */
				ieee802154: ieee802154 {
					compatible = "nordic,nrf-ieee802154"; /* in framework-zephyr\dts\vendor\nordic\nrf54l_05_10_15.dtsi:249 */
					status = "okay";                      /* in ..\platforms\Seeed Studio\zephyr\boards\arm\xiao_nrf54l15\xiao_nrf54l15_nrf54l15_cpuapp.dts:159 */
				};

				/* node '/soc/peripheral@50000000/radio@8a000/bt_hci_controller' defined in framework-zephyr\dts\vendor\nordic\nrf54l_05_10_15.dtsi:256 */
				bt_hci_controller: bt_hci_controller {
					compatible = "zephyr,bt-hci-ll-sw-split"; /* in framework-zephyr\dts\vendor\nordic\nrf54l_05_10_15.dtsi:257 */
					status = "okay";                          /* in framework-zephyr\dts\arm\nordic\nrf54l_05_10_15_cpuapp.dtsi:40 */
				};
			};

			/* node '/soc/peripheral@50000000/dppic@c2000' defined in framework-zephyr\dts\vendor\nordic\nrf54l_05_10_15.dtsi:262 */
			dppic20: dppic@c2000 {
				compatible = "nordic,nrf-dppic"; /* in framework-zephyr\dts\vendor\nordic\nrf54l_05_10_15.dtsi:263 */
				reg = < 0xc2000 0x808 >;         /* in framework-zephyr\dts\vendor\nordic\nrf54l_05_10_15.dtsi:264 */
				status = "okay";                 /* in framework-zephyr\dts\arm\nordic\nrf54l_05_10_15_cpuapp.dtsi:103 */
			};

			/* node '/soc/peripheral@50000000/ppib@c3000' defined in framework-zephyr\dts\vendor\nordic\nrf54l_05_10_15.dtsi:268 */
			ppib20: ppib@c3000 {
				compatible = "nordic,nrf-ppib"; /* in framework-zephyr\dts\vendor\nordic\nrf54l_05_10_15.dtsi:269 */
				reg = < 0xc3000 0x1000 >;       /* in framework-zephyr\dts\vendor\nordic\nrf54l_05_10_15.dtsi:270 */
				status = "okay";                /* in framework-zephyr\dts\arm\nordic\nrf54l_05_10_15_cpuapp.dtsi:127 */
			};

			/* node '/soc/peripheral@50000000/ppib@c4000' defined in framework-zephyr\dts\vendor\nordic\nrf54l_05_10_15.dtsi:274 */
			ppib21: ppib@c4000 {
				compatible = "nordic,nrf-ppib"; /* in framework-zephyr\dts\vendor\nordic\nrf54l_05_10_15.dtsi:275 */
				reg = < 0xc4000 0x1000 >;       /* in framework-zephyr\dts\vendor\nordic\nrf54l_05_10_15.dtsi:276 */
				status = "okay";                /* in framework-zephyr\dts\arm\nordic\nrf54l_05_10_15_cpuapp.dtsi:131 */
			};

			/* node '/soc/peripheral@50000000/ppib@c5000' defined in framework-zephyr\dts\vendor\nordic\nrf54l_05_10_15.dtsi:280 */
			ppib22: ppib@c5000 {
				compatible = "nordic,nrf-ppib"; /* in framework-zephyr\dts\vendor\nordic\nrf54l_05_10_15.dtsi:281 */
				reg = < 0xc5000 0x1000 >;       /* in framework-zephyr\dts\vendor\nordic\nrf54l_05_10_15.dtsi:282 */
				status = "okay";                /* in framework-zephyr\dts\arm\nordic\nrf54l_05_10_15_cpuapp.dtsi:135 */
			};

			/* node '/soc/peripheral@50000000/i2c@c6000' defined in framework-zephyr\dts\vendor\nordic\nrf54l_05_10_15.dtsi:286 */
			i2c20: i2c@c6000 {
				compatible = "nordic,nrf-twim"; /* in framework-zephyr\dts\vendor\nordic\nrf54l_05_10_15.dtsi:287 */
				#address-cells = < 0x1 >;       /* in framework-zephyr\dts\vendor\nordic\nrf54l_05_10_15.dtsi:288 */
				#size-cells = < 0x0 >;          /* in framework-zephyr\dts\vendor\nordic\nrf54l_05_10_15.dtsi:289 */
				reg = < 0xc6000 0x1000 >;       /* in framework-zephyr\dts\vendor\nordic\nrf54l_05_10_15.dtsi:290 */
				interrupts = < 0xc6 0x1 >;      /* in framework-zephyr\dts\vendor\nordic\nrf54l_05_10_15.dtsi:291 */
				easydma-maxcnt-bits = < 0x10 >; /* in framework-zephyr\dts\vendor\nordic\nrf54l_05_10_15.dtsi:292 */
				status = "disabled";            /* in framework-zephyr\dts\vendor\nordic\nrf54l_05_10_15.dtsi:293 */
				zephyr,pm-device-runtime-auto;  /* in framework-zephyr\dts\vendor\nordic\nrf54l_05_10_15.dtsi:294 */
			};

			/* node '/soc/peripheral@50000000/spi@c6000' defined in framework-zephyr\dts\vendor\nordic\nrf54l_05_10_15.dtsi:297 */
			spi20: spi@c6000 {
				compatible = "nordic,nrf-spim"; /* in framework-zephyr\dts\vendor\nordic\nrf54l_05_10_15.dtsi:304 */
				#address-cells = < 0x1 >;       /* in framework-zephyr\dts\vendor\nordic\nrf54l_05_10_15.dtsi:305 */
				#size-cells = < 0x0 >;          /* in framework-zephyr\dts\vendor\nordic\nrf54l_05_10_15.dtsi:306 */
				reg = < 0xc6000 0x1000 >;       /* in framework-zephyr\dts\vendor\nordic\nrf54l_05_10_15.dtsi:307 */
				interrupts = < 0xc6 0x1 >;      /* in framework-zephyr\dts\vendor\nordic\nrf54l_05_10_15.dtsi:308 */
				max-frequency = < 0x7a1200 >;   /* in framework-zephyr\dts\vendor\nordic\nrf54l_05_10_15.dtsi:309 */
				easydma-maxcnt-bits = < 0x10 >; /* in framework-zephyr\dts\vendor\nordic\nrf54l_05_10_15.dtsi:310 */
				rx-delay-supported;             /* in framework-zephyr\dts\vendor\nordic\nrf54l_05_10_15.dtsi:311 */
				rx-delay = < 0x1 >;             /* in framework-zephyr\dts\vendor\nordic\nrf54l_05_10_15.dtsi:312 */
				status = "disabled";            /* in framework-zephyr\dts\vendor\nordic\nrf54l_05_10_15.dtsi:313 */
			};

			/* node '/soc/peripheral@50000000/uart@c6000' defined in framework-zephyr\dts\vendor\nordic\nrf54l_05_10_15.dtsi:316 */
			uart20: uart@c6000 {
				compatible = "nordic,nrf-uarte"; /* in framework-zephyr\dts\vendor\nordic\nrf54l_05_10_15.dtsi:317 */
				reg = < 0xc6000 0x1000 >;        /* in framework-zephyr\dts\vendor\nordic\nrf54l_05_10_15.dtsi:318 */
				interrupts = < 0xc6 0x1 >;       /* in framework-zephyr\dts\vendor\nordic\nrf54l_05_10_15.dtsi:319 */
				endtx-stoptx-supported;          /* in framework-zephyr\dts\vendor\nordic\nrf54l_05_10_15.dtsi:321 */
				frame-timeout-supported;         /* in framework-zephyr\dts\vendor\nordic\nrf54l_05_10_15.dtsi:322 */
				current-speed = < 0x1c200 >;     /* in ..\platforms\Seeed Studio\zephyr\boards\arm\xiao_nrf54l15\xiao_nrf54l15_common.dtsi:38 */
				pinctrl-0 = < &uart20_default >; /* in ..\platforms\Seeed Studio\zephyr\boards\arm\xiao_nrf54l15\xiao_nrf54l15_common.dtsi:39 */
				pinctrl-1 = < &uart20_sleep >;   /* in ..\platforms\Seeed Studio\zephyr\boards\arm\xiao_nrf54l15\xiao_nrf54l15_common.dtsi:40 */
				pinctrl-names = "default",
				                "sleep";         /* in ..\platforms\Seeed Studio\zephyr\boards\arm\xiao_nrf54l15\xiao_nrf54l15_common.dtsi:41 */
				status = "okay";                 /* in ..\platforms\Seeed Studio\zephyr\boards\arm\xiao_nrf54l15\xiao_nrf54l15_nrf54l15_cpuapp.dts:76 */
			};

			/* node '/soc/peripheral@50000000/i2c@c7000' defined in framework-zephyr\dts\vendor\nordic\nrf54l_05_10_15.dtsi:325 */
			i2c21: i2c@c7000 {
				compatible = "nordic,nrf-twim"; /* in framework-zephyr\dts\vendor\nordic\nrf54l_05_10_15.dtsi:326 */
				#address-cells = < 0x1 >;       /* in framework-zephyr\dts\vendor\nordic\nrf54l_05_10_15.dtsi:327 */
				#size-cells = < 0x0 >;          /* in framework-zephyr\dts\vendor\nordic\nrf54l_05_10_15.dtsi:328 */
				reg = < 0xc7000 0x1000 >;       /* in framework-zephyr\dts\vendor\nordic\nrf54l_05_10_15.dtsi:329 */
				interrupts = < 0xc7 0x1 >;      /* in framework-zephyr\dts\vendor\nordic\nrf54l_05_10_15.dtsi:330 */
				easydma-maxcnt-bits = < 0x10 >; /* in framework-zephyr\dts\vendor\nordic\nrf54l_05_10_15.dtsi:331 */
				status = "disabled";            /* in framework-zephyr\dts\vendor\nordic\nrf54l_05_10_15.dtsi:332 */
				zephyr,pm-device-runtime-auto;  /* in framework-zephyr\dts\vendor\nordic\nrf54l_05_10_15.dtsi:333 */
			};

			/* node '/soc/peripheral@50000000/spi@c7000' defined in framework-zephyr\dts\vendor\nordic\nrf54l_05_10_15.dtsi:336 */
			spi21: spi@c7000 {
				compatible = "nordic,nrf-spim"; /* in framework-zephyr\dts\vendor\nordic\nrf54l_05_10_15.dtsi:343 */
				#address-cells = < 0x1 >;       /* in framework-zephyr\dts\vendor\nordic\nrf54l_05_10_15.dtsi:344 */
				#size-cells = < 0x0 >;          /* in framework-zephyr\dts\vendor\nordic\nrf54l_05_10_15.dtsi:345 */
				reg = < 0xc7000 0x1000 >;       /* in framework-zephyr\dts\vendor\nordic\nrf54l_05_10_15.dtsi:346 */
				interrupts = < 0xc7 0x1 >;      /* in framework-zephyr\dts\vendor\nordic\nrf54l_05_10_15.dtsi:347 */
				max-frequency = < 0x7a1200 >;   /* in framework-zephyr\dts\vendor\nordic\nrf54l_05_10_15.dtsi:348 */
				easydma-maxcnt-bits = < 0x10 >; /* in framework-zephyr\dts\vendor\nordic\nrf54l_05_10_15.dtsi:349 */
				rx-delay-supported;             /* in framework-zephyr\dts\vendor\nordic\nrf54l_05_10_15.dtsi:350 */
				rx-delay = < 0x1 >;             /* in framework-zephyr\dts\vendor\nordic\nrf54l_05_10_15.dtsi:351 */
				status = "disabled";            /* in framework-zephyr\dts\vendor\nordic\nrf54l_05_10_15.dtsi:352 */
			};

			/* node '/soc/peripheral@50000000/uart@c7000' defined in framework-zephyr\dts\vendor\nordic\nrf54l_05_10_15.dtsi:355 */
			uart21: xiao_serial: uart@c7000 {
				compatible = "nordic,nrf-uarte"; /* in framework-zephyr\dts\vendor\nordic\nrf54l_05_10_15.dtsi:356 */
				reg = < 0xc7000 0x1000 >;        /* in framework-zephyr\dts\vendor\nordic\nrf54l_05_10_15.dtsi:357 */
				interrupts = < 0xc7 0x1 >;       /* in framework-zephyr\dts\vendor\nordic\nrf54l_05_10_15.dtsi:358 */
				endtx-stoptx-supported;          /* in framework-zephyr\dts\vendor\nordic\nrf54l_05_10_15.dtsi:360 */
				frame-timeout-supported;         /* in framework-zephyr\dts\vendor\nordic\nrf54l_05_10_15.dtsi:361 */
				current-speed = < 0x1c200 >;     /* in ..\platforms\Seeed Studio\zephyr\boards\arm\xiao_nrf54l15\xiao_nrf54l15_common.dtsi:45 */
				pinctrl-0 = < &uart21_default >; /* in ..\platforms\Seeed Studio\zephyr\boards\arm\xiao_nrf54l15\xiao_nrf54l15_common.dtsi:46 */
				pinctrl-1 = < &uart21_sleep >;   /* in ..\platforms\Seeed Studio\zephyr\boards\arm\xiao_nrf54l15\xiao_nrf54l15_common.dtsi:47 */
				pinctrl-names = "default",
				                "sleep";         /* in ..\platforms\Seeed Studio\zephyr\boards\arm\xiao_nrf54l15\xiao_nrf54l15_common.dtsi:48 */
				status = "okay";                 /* in ..\platforms\Seeed Studio\zephyr\boards\arm\xiao_nrf54l15\xiao_nrf54l15_nrf54l15_cpuapp.dts:80 */
			};

			/* node '/soc/peripheral@50000000/i2c@c8000' defined in framework-zephyr\dts\vendor\nordic\nrf54l_05_10_15.dtsi:364 */
			i2c22: xiao_i2c: i2c@c8000 {
				compatible = "nordic,nrf-twim"; /* in framework-zephyr\dts\vendor\nordic\nrf54l_05_10_15.dtsi:365 */
				#address-cells = < 0x1 >;       /* in framework-zephyr\dts\vendor\nordic\nrf54l_05_10_15.dtsi:366 */
				#size-cells = < 0x0 >;          /* in framework-zephyr\dts\vendor\nordic\nrf54l_05_10_15.dtsi:367 */
				reg = < 0xc8000 0x1000 >;       /* in framework-zephyr\dts\vendor\nordic\nrf54l_05_10_15.dtsi:368 */
				interrupts = < 0xc8 0x1 >;      /* in framework-zephyr\dts\vendor\nordic\nrf54l_05_10_15.dtsi:369 */
				easydma-maxcnt-bits = < 0x10 >; /* in framework-zephyr\dts\vendor\nordic\nrf54l_05_10_15.dtsi:370 */
				zephyr,pm-device-runtime-auto;  /* in framework-zephyr\dts\vendor\nordic\nrf54l_05_10_15.dtsi:372 */
				pinctrl-0 = < &i2c22_default >; /* in ..\platforms\Seeed Studio\zephyr\boards\arm\xiao_nrf54l15\xiao_nrf54l15_common.dtsi:52 */
				pinctrl-1 = < &i2c22_sleep >;   /* in ..\platforms\Seeed Studio\zephyr\boards\arm\xiao_nrf54l15\xiao_nrf54l15_common.dtsi:53 */
				pinctrl-names = "default",
				                "sleep";        /* in ..\platforms\Seeed Studio\zephyr\boards\arm\xiao_nrf54l15\xiao_nrf54l15_common.dtsi:54 */
				clock-frequency = < 0x61a80 >;  /* in ..\platforms\Seeed Studio\zephyr\boards\arm\xiao_nrf54l15\xiao_nrf54l15_common.dtsi:55 */
				status = "okay";                /* in ..\platforms\Seeed Studio\zephyr\boards\arm\xiao_nrf54l15\xiao_nrf54l15_nrf54l15_cpuapp.dts:84 */
			};

			/* node '/soc/peripheral@50000000/spi@c8000' defined in framework-zephyr\dts\vendor\nordic\nrf54l_05_10_15.dtsi:375 */
			spi22: spi@c8000 {
				compatible = "nordic,nrf-spim"; /* in framework-zephyr\dts\vendor\nordic\nrf54l_05_10_15.dtsi:382 */
				#address-cells = < 0x1 >;       /* in framework-zephyr\dts\vendor\nordic\nrf54l_05_10_15.dtsi:383 */
				#size-cells = < 0x0 >;          /* in framework-zephyr\dts\vendor\nordic\nrf54l_05_10_15.dtsi:384 */
				reg = < 0xc8000 0x1000 >;       /* in framework-zephyr\dts\vendor\nordic\nrf54l_05_10_15.dtsi:385 */
				interrupts = < 0xc8 0x1 >;      /* in framework-zephyr\dts\vendor\nordic\nrf54l_05_10_15.dtsi:386 */
				max-frequency = < 0x7a1200 >;   /* in framework-zephyr\dts\vendor\nordic\nrf54l_05_10_15.dtsi:387 */
				easydma-maxcnt-bits = < 0x10 >; /* in framework-zephyr\dts\vendor\nordic\nrf54l_05_10_15.dtsi:388 */
				rx-delay-supported;             /* in framework-zephyr\dts\vendor\nordic\nrf54l_05_10_15.dtsi:389 */
				rx-delay = < 0x1 >;             /* in framework-zephyr\dts\vendor\nordic\nrf54l_05_10_15.dtsi:390 */
				status = "disabled";            /* in framework-zephyr\dts\vendor\nordic\nrf54l_05_10_15.dtsi:391 */
				pinctrl-0 = < &spi22_default >; /* in ..\platforms\Seeed Studio\zephyr\boards\arm\xiao_nrf54l15\xiao_nrf54l15_common.dtsi:72 */
				pinctrl-1 = < &spi22_sleep >;   /* in ..\platforms\Seeed Studio\zephyr\boards\arm\xiao_nrf54l15\xiao_nrf54l15_common.dtsi:73 */
				pinctrl-names = "default",
				                "sleep";        /* in ..\platforms\Seeed Studio\zephyr\boards\arm\xiao_nrf54l15\xiao_nrf54l15_common.dtsi:74 */
			};

			/* node '/soc/peripheral@50000000/uart@c8000' defined in framework-zephyr\dts\vendor\nordic\nrf54l_05_10_15.dtsi:394 */
			uart22: uart@c8000 {
				compatible = "nordic,nrf-uarte"; /* in framework-zephyr\dts\vendor\nordic\nrf54l_05_10_15.dtsi:395 */
				reg = < 0xc8000 0x1000 >;        /* in framework-zephyr\dts\vendor\nordic\nrf54l_05_10_15.dtsi:396 */
				interrupts = < 0xc8 0x1 >;       /* in framework-zephyr\dts\vendor\nordic\nrf54l_05_10_15.dtsi:397 */
				status = "disabled";             /* in framework-zephyr\dts\vendor\nordic\nrf54l_05_10_15.dtsi:398 */
				endtx-stoptx-supported;          /* in framework-zephyr\dts\vendor\nordic\nrf54l_05_10_15.dtsi:399 */
				frame-timeout-supported;         /* in framework-zephyr\dts\vendor\nordic\nrf54l_05_10_15.dtsi:400 */
			};

			/* node '/soc/peripheral@50000000/egu@c9000' defined in framework-zephyr\dts\vendor\nordic\nrf54l_05_10_15.dtsi:403 */
			egu20: egu@c9000 {
				compatible = "nordic,nrf-egu"; /* in framework-zephyr\dts\vendor\nordic\nrf54l_05_10_15.dtsi:404 */
				reg = < 0xc9000 0x1000 >;      /* in framework-zephyr\dts\vendor\nordic\nrf54l_05_10_15.dtsi:405 */
				interrupts = < 0xc9 0x1 >;     /* in framework-zephyr\dts\vendor\nordic\nrf54l_05_10_15.dtsi:406 */
				status = "disabled";           /* in framework-zephyr\dts\vendor\nordic\nrf54l_05_10_15.dtsi:407 */
			};

			/* node '/soc/peripheral@50000000/timer@ca000' defined in framework-zephyr\dts\vendor\nordic\nrf54l_05_10_15.dtsi:410 */
			timer20: timer@ca000 {
				compatible = "nordic,nrf-timer"; /* in framework-zephyr\dts\vendor\nordic\nrf54l_05_10_15.dtsi:411 */
				status = "disabled";             /* in framework-zephyr\dts\vendor\nordic\nrf54l_05_10_15.dtsi:412 */
				reg = < 0xca000 0x1000 >;        /* in framework-zephyr\dts\vendor\nordic\nrf54l_05_10_15.dtsi:413 */
				cc-num = < 0x6 >;                /* in framework-zephyr\dts\vendor\nordic\nrf54l_05_10_15.dtsi:414 */
				max-bit-width = < 0x20 >;        /* in framework-zephyr\dts\vendor\nordic\nrf54l_05_10_15.dtsi:415 */
				interrupts = < 0xca 0x1 >;       /* in framework-zephyr\dts\vendor\nordic\nrf54l_05_10_15.dtsi:416 */
				prescaler = < 0x0 >;             /* in framework-zephyr\dts\vendor\nordic\nrf54l_05_10_15.dtsi:417 */
			};

			/* node '/soc/peripheral@50000000/timer@cb000' defined in framework-zephyr\dts\vendor\nordic\nrf54l_05_10_15.dtsi:420 */
			timer21: timer@cb000 {
				compatible = "nordic,nrf-timer"; /* in framework-zephyr\dts\vendor\nordic\nrf54l_05_10_15.dtsi:421 */
				status = "disabled";             /* in framework-zephyr\dts\vendor\nordic\nrf54l_05_10_15.dtsi:422 */
				reg = < 0xcb000 0x1000 >;        /* in framework-zephyr\dts\vendor\nordic\nrf54l_05_10_15.dtsi:423 */
				cc-num = < 0x6 >;                /* in framework-zephyr\dts\vendor\nordic\nrf54l_05_10_15.dtsi:424 */
				max-bit-width = < 0x20 >;        /* in framework-zephyr\dts\vendor\nordic\nrf54l_05_10_15.dtsi:425 */
				interrupts = < 0xcb 0x1 >;       /* in framework-zephyr\dts\vendor\nordic\nrf54l_05_10_15.dtsi:426 */
				prescaler = < 0x0 >;             /* in framework-zephyr\dts\vendor\nordic\nrf54l_05_10_15.dtsi:427 */
			};

			/* node '/soc/peripheral@50000000/timer@cc000' defined in framework-zephyr\dts\vendor\nordic\nrf54l_05_10_15.dtsi:430 */
			timer22: timer@cc000 {
				compatible = "nordic,nrf-timer"; /* in framework-zephyr\dts\vendor\nordic\nrf54l_05_10_15.dtsi:431 */
				status = "disabled";             /* in framework-zephyr\dts\vendor\nordic\nrf54l_05_10_15.dtsi:432 */
				reg = < 0xcc000 0x1000 >;        /* in framework-zephyr\dts\vendor\nordic\nrf54l_05_10_15.dtsi:433 */
				cc-num = < 0x6 >;                /* in framework-zephyr\dts\vendor\nordic\nrf54l_05_10_15.dtsi:434 */
				max-bit-width = < 0x20 >;        /* in framework-zephyr\dts\vendor\nordic\nrf54l_05_10_15.dtsi:435 */
				interrupts = < 0xcc 0x1 >;       /* in framework-zephyr\dts\vendor\nordic\nrf54l_05_10_15.dtsi:436 */
				prescaler = < 0x0 >;             /* in framework-zephyr\dts\vendor\nordic\nrf54l_05_10_15.dtsi:437 */
			};

			/* node '/soc/peripheral@50000000/timer@cd000' defined in framework-zephyr\dts\vendor\nordic\nrf54l_05_10_15.dtsi:440 */
			timer23: timer@cd000 {
				compatible = "nordic,nrf-timer"; /* in framework-zephyr\dts\vendor\nordic\nrf54l_05_10_15.dtsi:441 */
				status = "disabled";             /* in framework-zephyr\dts\vendor\nordic\nrf54l_05_10_15.dtsi:442 */
				reg = < 0xcd000 0x1000 >;        /* in framework-zephyr\dts\vendor\nordic\nrf54l_05_10_15.dtsi:443 */
				cc-num = < 0x6 >;                /* in framework-zephyr\dts\vendor\nordic\nrf54l_05_10_15.dtsi:444 */
				max-bit-width = < 0x20 >;        /* in framework-zephyr\dts\vendor\nordic\nrf54l_05_10_15.dtsi:445 */
				interrupts = < 0xcd 0x1 >;       /* in framework-zephyr\dts\vendor\nordic\nrf54l_05_10_15.dtsi:446 */
				prescaler = < 0x0 >;             /* in framework-zephyr\dts\vendor\nordic\nrf54l_05_10_15.dtsi:447 */
			};

			/* node '/soc/peripheral@50000000/timer@ce000' defined in framework-zephyr\dts\vendor\nordic\nrf54l_05_10_15.dtsi:450 */
			timer24: timer@ce000 {
				compatible = "nordic,nrf-timer"; /* in framework-zephyr\dts\vendor\nordic\nrf54l_05_10_15.dtsi:451 */
				status = "disabled";             /* in framework-zephyr\dts\vendor\nordic\nrf54l_05_10_15.dtsi:452 */
				reg = < 0xce000 0x1000 >;        /* in framework-zephyr\dts\vendor\nordic\nrf54l_05_10_15.dtsi:453 */
				cc-num = < 0x6 >;                /* in framework-zephyr\dts\vendor\nordic\nrf54l_05_10_15.dtsi:454 */
				max-bit-width = < 0x20 >;        /* in framework-zephyr\dts\vendor\nordic\nrf54l_05_10_15.dtsi:455 */
				interrupts = < 0xce 0x1 >;       /* in framework-zephyr\dts\vendor\nordic\nrf54l_05_10_15.dtsi:456 */
				prescaler = < 0x0 >;             /* in framework-zephyr\dts\vendor\nordic\nrf54l_05_10_15.dtsi:457 */
			};

			/* node '/soc/peripheral@50000000/pdm@d0000' defined in framework-zephyr\dts\vendor\nordic\nrf54l_05_10_15.dtsi:460 */
			pdm20: pdm@d0000 {
				compatible = "nordic,nrf-pdm";  /* in framework-zephyr\dts\vendor\nordic\nrf54l_05_10_15.dtsi:461 */
				reg = < 0xd0000 0x1000 >;       /* in framework-zephyr\dts\vendor\nordic\nrf54l_05_10_15.dtsi:463 */
				interrupts = < 0xd0 0x1 >;      /* in framework-zephyr\dts\vendor\nordic\nrf54l_05_10_15.dtsi:464 */
				pinctrl-0 = < &pdm20_default >; /* in ..\platforms\Seeed Studio\zephyr\boards\arm\xiao_nrf54l15\xiao_nrf54l15_common.dtsi:78 */
				pinctrl-names = "default";      /* in ..\platforms\Seeed Studio\zephyr\boards\arm\xiao_nrf54l15\xiao_nrf54l15_common.dtsi:79 */
				clock-source = "PCLK32M";       /* in ..\platforms\Seeed Studio\zephyr\boards\arm\xiao_nrf54l15\xiao_nrf54l15_common.dtsi:80 */
				status = "okay";                /* in ..\platforms\Seeed Studio\zephyr\boards\arm\xiao_nrf54l15\xiao_nrf54l15_nrf54l15_cpuapp.dts:103 */
			};

			/* node '/soc/peripheral@50000000/pdm@d1000' defined in framework-zephyr\dts\vendor\nordic\nrf54l_05_10_15.dtsi:467 */
			pdm21: pdm@d1000 {
				compatible = "nordic,nrf-pdm"; /* in framework-zephyr\dts\vendor\nordic\nrf54l_05_10_15.dtsi:468 */
				status = "disabled";           /* in framework-zephyr\dts\vendor\nordic\nrf54l_05_10_15.dtsi:469 */
				reg = < 0xd1000 0x1000 >;      /* in framework-zephyr\dts\vendor\nordic\nrf54l_05_10_15.dtsi:470 */
				interrupts = < 0xd1 0x1 >;     /* in framework-zephyr\dts\vendor\nordic\nrf54l_05_10_15.dtsi:471 */
			};

			/* node '/soc/peripheral@50000000/pwm@d2000' defined in framework-zephyr\dts\vendor\nordic\nrf54l_05_10_15.dtsi:474 */
			pwm20: pwm@d2000 {
				compatible = "nordic,nrf-pwm"; /* in framework-zephyr\dts\vendor\nordic\nrf54l_05_10_15.dtsi:475 */
				status = "disabled";           /* in framework-zephyr\dts\vendor\nordic\nrf54l_05_10_15.dtsi:476 */
				reg = < 0xd2000 0x1000 >;      /* in framework-zephyr\dts\vendor\nordic\nrf54l_05_10_15.dtsi:477 */
				interrupts = < 0xd2 0x1 >;     /* in framework-zephyr\dts\vendor\nordic\nrf54l_05_10_15.dtsi:478 */
				#pwm-cells = < 0x3 >;          /* in framework-zephyr\dts\vendor\nordic\nrf54l_05_10_15.dtsi:479 */
				idleout-supported;             /* in framework-zephyr\dts\vendor\nordic\nrf54l_05_10_15.dtsi:480 */
			};

			/* node '/soc/peripheral@50000000/pwm@d3000' defined in framework-zephyr\dts\vendor\nordic\nrf54l_05_10_15.dtsi:483 */
			pwm21: pwm@d3000 {
				compatible = "nordic,nrf-pwm"; /* in framework-zephyr\dts\vendor\nordic\nrf54l_05_10_15.dtsi:484 */
				status = "disabled";           /* in framework-zephyr\dts\vendor\nordic\nrf54l_05_10_15.dtsi:485 */
				reg = < 0xd3000 0x1000 >;      /* in framework-zephyr\dts\vendor\nordic\nrf54l_05_10_15.dtsi:486 */
				interrupts = < 0xd3 0x1 >;     /* in framework-zephyr\dts\vendor\nordic\nrf54l_05_10_15.dtsi:487 */
				#pwm-cells = < 0x3 >;          /* in framework-zephyr\dts\vendor\nordic\nrf54l_05_10_15.dtsi:488 */
				idleout-supported;             /* in framework-zephyr\dts\vendor\nordic\nrf54l_05_10_15.dtsi:489 */
			};

			/* node '/soc/peripheral@50000000/pwm@d4000' defined in framework-zephyr\dts\vendor\nordic\nrf54l_05_10_15.dtsi:492 */
			pwm22: pwm@d4000 {
				compatible = "nordic,nrf-pwm"; /* in framework-zephyr\dts\vendor\nordic\nrf54l_05_10_15.dtsi:493 */
				status = "disabled";           /* in framework-zephyr\dts\vendor\nordic\nrf54l_05_10_15.dtsi:494 */
				reg = < 0xd4000 0x1000 >;      /* in framework-zephyr\dts\vendor\nordic\nrf54l_05_10_15.dtsi:495 */
				interrupts = < 0xd4 0x1 >;     /* in framework-zephyr\dts\vendor\nordic\nrf54l_05_10_15.dtsi:496 */
				#pwm-cells = < 0x3 >;          /* in framework-zephyr\dts\vendor\nordic\nrf54l_05_10_15.dtsi:497 */
				idleout-supported;             /* in framework-zephyr\dts\vendor\nordic\nrf54l_05_10_15.dtsi:498 */
			};

			/* node '/soc/peripheral@50000000/adc@d5000' defined in framework-zephyr\dts\vendor\nordic\nrf54l_05_10_15.dtsi:501 */
			adc: xiao_adc: adc@d5000 {
				compatible = "nordic,nrf-saadc"; /* in framework-zephyr\dts\vendor\nordic\nrf54l_05_10_15.dtsi:502 */
				reg = < 0xd5000 0x1000 >;        /* in framework-zephyr\dts\vendor\nordic\nrf54l_05_10_15.dtsi:503 */
				interrupts = < 0xd5 0x1 >;       /* in framework-zephyr\dts\vendor\nordic\nrf54l_05_10_15.dtsi:504 */
				#io-channel-cells = < 0x1 >;     /* in framework-zephyr\dts\vendor\nordic\nrf54l_05_10_15.dtsi:506 */
				zephyr,pm-device-runtime-auto;   /* in framework-zephyr\dts\vendor\nordic\nrf54l_05_10_15.dtsi:507 */
				#address-cells = < 0x1 >;        /* in ..\platforms\Seeed Studio\zephyr\boards\arm\xiao_nrf54l15\xiao_nrf54l15_common.dtsi:85 */
				#size-cells = < 0x0 >;           /* in ..\platforms\Seeed Studio\zephyr\boards\arm\xiao_nrf54l15\xiao_nrf54l15_common.dtsi:86 */
				status = "okay";                 /* in ..\platforms\Seeed Studio\zephyr\boards\arm\xiao_nrf54l15\xiao_nrf54l15_nrf54l15_cpuapp.dts:107 */

				/* node '/soc/peripheral@50000000/adc@d5000/channel@0' defined in ..\platforms\Seeed Studio\zephyr\boards\arm\xiao_nrf54l15\xiao_nrf54l15_common.dtsi:88 */
				channel@0 {
					reg = < 0x0 >;                         /* in ..\platforms\Seeed Studio\zephyr\boards\arm\xiao_nrf54l15\xiao_nrf54l15_common.dtsi:89 */
					zephyr,gain = "ADC_GAIN_1_4";          /* in ..\platforms\Seeed Studio\zephyr\boards\arm\xiao_nrf54l15\xiao_nrf54l15_common.dtsi:90 */
					zephyr,reference = "ADC_REF_INTERNAL"; /* in ..\platforms\Seeed Studio\zephyr\boards\arm\xiao_nrf54l15\xiao_nrf54l15_common.dtsi:91 */
					zephyr,acquisition-time = < 0x0 >;     /* in ..\platforms\Seeed Studio\zephyr\boards\arm\xiao_nrf54l15\xiao_nrf54l15_common.dtsi:92 */
					zephyr,input-positive = < 0x1 >;       /* in ..\platforms\Seeed Studio\zephyr\boards\arm\xiao_nrf54l15\xiao_nrf54l15_common.dtsi:93 */
					zephyr,resolution = < 0xc >;           /* in ..\platforms\Seeed Studio\zephyr\boards\arm\xiao_nrf54l15\xiao_nrf54l15_common.dtsi:94 */
					zephyr,oversampling = < 0x8 >;         /* in ..\platforms\Seeed Studio\zephyr\boards\arm\xiao_nrf54l15\xiao_nrf54l15_common.dtsi:95 */
				};

				/* node '/soc/peripheral@50000000/adc@d5000/channel@1' defined in ..\platforms\Seeed Studio\zephyr\boards\arm\xiao_nrf54l15\xiao_nrf54l15_common.dtsi:98 */
				channel@1 {
					reg = < 0x1 >;                         /* in ..\platforms\Seeed Studio\zephyr\boards\arm\xiao_nrf54l15\xiao_nrf54l15_common.dtsi:99 */
					zephyr,gain = "ADC_GAIN_1_4";          /* in ..\platforms\Seeed Studio\zephyr\boards\arm\xiao_nrf54l15\xiao_nrf54l15_common.dtsi:100 */
					zephyr,reference = "ADC_REF_INTERNAL"; /* in ..\platforms\Seeed Studio\zephyr\boards\arm\xiao_nrf54l15\xiao_nrf54l15_common.dtsi:101 */
					zephyr,acquisition-time = < 0x0 >;     /* in ..\platforms\Seeed Studio\zephyr\boards\arm\xiao_nrf54l15\xiao_nrf54l15_common.dtsi:102 */
					zephyr,input-positive = < 0x2 >;       /* in ..\platforms\Seeed Studio\zephyr\boards\arm\xiao_nrf54l15\xiao_nrf54l15_common.dtsi:103 */
					zephyr,resolution = < 0xc >;           /* in ..\platforms\Seeed Studio\zephyr\boards\arm\xiao_nrf54l15\xiao_nrf54l15_common.dtsi:104 */
					zephyr,oversampling = < 0x8 >;         /* in ..\platforms\Seeed Studio\zephyr\boards\arm\xiao_nrf54l15\xiao_nrf54l15_common.dtsi:105 */
				};

				/* node '/soc/peripheral@50000000/adc@d5000/channel@2' defined in ..\platforms\Seeed Studio\zephyr\boards\arm\xiao_nrf54l15\xiao_nrf54l15_common.dtsi:108 */
				channel@2 {
					reg = < 0x2 >;                         /* in ..\platforms\Seeed Studio\zephyr\boards\arm\xiao_nrf54l15\xiao_nrf54l15_common.dtsi:109 */
					zephyr,gain = "ADC_GAIN_1_4";          /* in ..\platforms\Seeed Studio\zephyr\boards\arm\xiao_nrf54l15\xiao_nrf54l15_common.dtsi:110 */
					zephyr,reference = "ADC_REF_INTERNAL"; /* in ..\platforms\Seeed Studio\zephyr\boards\arm\xiao_nrf54l15\xiao_nrf54l15_common.dtsi:111 */
					zephyr,acquisition-time = < 0x0 >;     /* in ..\platforms\Seeed Studio\zephyr\boards\arm\xiao_nrf54l15\xiao_nrf54l15_common.dtsi:112 */
					zephyr,input-positive = < 0x3 >;       /* in ..\platforms\Seeed Studio\zephyr\boards\arm\xiao_nrf54l15\xiao_nrf54l15_common.dtsi:113 */
					zephyr,resolution = < 0xc >;           /* in ..\platforms\Seeed Studio\zephyr\boards\arm\xiao_nrf54l15\xiao_nrf54l15_common.dtsi:114 */
					zephyr,oversampling = < 0x8 >;         /* in ..\platforms\Seeed Studio\zephyr\boards\arm\xiao_nrf54l15\xiao_nrf54l15_common.dtsi:115 */
				};

				/* node '/soc/peripheral@50000000/adc@d5000/channel@3' defined in ..\platforms\Seeed Studio\zephyr\boards\arm\xiao_nrf54l15\xiao_nrf54l15_common.dtsi:118 */
				channel@3 {
					reg = < 0x3 >;                         /* in ..\platforms\Seeed Studio\zephyr\boards\arm\xiao_nrf54l15\xiao_nrf54l15_common.dtsi:119 */
					zephyr,gain = "ADC_GAIN_1_4";          /* in ..\platforms\Seeed Studio\zephyr\boards\arm\xiao_nrf54l15\xiao_nrf54l15_common.dtsi:120 */
					zephyr,reference = "ADC_REF_INTERNAL"; /* in ..\platforms\Seeed Studio\zephyr\boards\arm\xiao_nrf54l15\xiao_nrf54l15_common.dtsi:121 */
					zephyr,acquisition-time = < 0x0 >;     /* in ..\platforms\Seeed Studio\zephyr\boards\arm\xiao_nrf54l15\xiao_nrf54l15_common.dtsi:122 */
					zephyr,input-positive = < 0x4 >;       /* in ..\platforms\Seeed Studio\zephyr\boards\arm\xiao_nrf54l15\xiao_nrf54l15_common.dtsi:123 */
					zephyr,resolution = < 0xc >;           /* in ..\platforms\Seeed Studio\zephyr\boards\arm\xiao_nrf54l15\xiao_nrf54l15_common.dtsi:124 */
					zephyr,oversampling = < 0x8 >;         /* in ..\platforms\Seeed Studio\zephyr\boards\arm\xiao_nrf54l15\xiao_nrf54l15_common.dtsi:125 */
				};

				/* node '/soc/peripheral@50000000/adc@d5000/channel@4' defined in ..\platforms\Seeed Studio\zephyr\boards\arm\xiao_nrf54l15\xiao_nrf54l15_common.dtsi:128 */
				channel@4 {
					reg = < 0x4 >;                         /* in ..\platforms\Seeed Studio\zephyr\boards\arm\xiao_nrf54l15\xiao_nrf54l15_common.dtsi:129 */
					zephyr,gain = "ADC_GAIN_1_4";          /* in ..\platforms\Seeed Studio\zephyr\boards\arm\xiao_nrf54l15\xiao_nrf54l15_common.dtsi:130 */
					zephyr,reference = "ADC_REF_INTERNAL"; /* in ..\platforms\Seeed Studio\zephyr\boards\arm\xiao_nrf54l15\xiao_nrf54l15_common.dtsi:131 */
					zephyr,acquisition-time = < 0x0 >;     /* in ..\platforms\Seeed Studio\zephyr\boards\arm\xiao_nrf54l15\xiao_nrf54l15_common.dtsi:132 */
					zephyr,input-positive = < 0x5 >;       /* in ..\platforms\Seeed Studio\zephyr\boards\arm\xiao_nrf54l15\xiao_nrf54l15_common.dtsi:133 */
					zephyr,resolution = < 0xc >;           /* in ..\platforms\Seeed Studio\zephyr\boards\arm\xiao_nrf54l15\xiao_nrf54l15_common.dtsi:134 */
					zephyr,oversampling = < 0x8 >;         /* in ..\platforms\Seeed Studio\zephyr\boards\arm\xiao_nrf54l15\xiao_nrf54l15_common.dtsi:135 */
				};

				/* node '/soc/peripheral@50000000/adc@d5000/channel@5' defined in ..\platforms\Seeed Studio\zephyr\boards\arm\xiao_nrf54l15\xiao_nrf54l15_common.dtsi:138 */
				channel@5 {
					reg = < 0x5 >;                         /* in ..\platforms\Seeed Studio\zephyr\boards\arm\xiao_nrf54l15\xiao_nrf54l15_common.dtsi:139 */
					zephyr,gain = "ADC_GAIN_1_4";          /* in ..\platforms\Seeed Studio\zephyr\boards\arm\xiao_nrf54l15\xiao_nrf54l15_common.dtsi:140 */
					zephyr,reference = "ADC_REF_INTERNAL"; /* in ..\platforms\Seeed Studio\zephyr\boards\arm\xiao_nrf54l15\xiao_nrf54l15_common.dtsi:141 */
					zephyr,acquisition-time = < 0x0 >;     /* in ..\platforms\Seeed Studio\zephyr\boards\arm\xiao_nrf54l15\xiao_nrf54l15_common.dtsi:142 */
					zephyr,input-positive = < 0x6 >;       /* in ..\platforms\Seeed Studio\zephyr\boards\arm\xiao_nrf54l15\xiao_nrf54l15_common.dtsi:143 */
					zephyr,resolution = < 0xc >;           /* in ..\platforms\Seeed Studio\zephyr\boards\arm\xiao_nrf54l15\xiao_nrf54l15_common.dtsi:144 */
					zephyr,oversampling = < 0x8 >;         /* in ..\platforms\Seeed Studio\zephyr\boards\arm\xiao_nrf54l15\xiao_nrf54l15_common.dtsi:145 */
				};

				/* node '/soc/peripheral@50000000/adc@d5000/channel@6' defined in ..\platforms\Seeed Studio\zephyr\boards\arm\xiao_nrf54l15\xiao_nrf54l15_common.dtsi:148 */
				channel@6 {
					reg = < 0x6 >;                         /* in ..\platforms\Seeed Studio\zephyr\boards\arm\xiao_nrf54l15\xiao_nrf54l15_common.dtsi:149 */
					zephyr,gain = "ADC_GAIN_1_4";          /* in ..\platforms\Seeed Studio\zephyr\boards\arm\xiao_nrf54l15\xiao_nrf54l15_common.dtsi:150 */
					zephyr,reference = "ADC_REF_INTERNAL"; /* in ..\platforms\Seeed Studio\zephyr\boards\arm\xiao_nrf54l15\xiao_nrf54l15_common.dtsi:151 */
					zephyr,acquisition-time = < 0x0 >;     /* in ..\platforms\Seeed Studio\zephyr\boards\arm\xiao_nrf54l15\xiao_nrf54l15_common.dtsi:152 */
					zephyr,input-positive = < 0x7 >;       /* in ..\platforms\Seeed Studio\zephyr\boards\arm\xiao_nrf54l15\xiao_nrf54l15_common.dtsi:153 */
					zephyr,resolution = < 0xc >;           /* in ..\platforms\Seeed Studio\zephyr\boards\arm\xiao_nrf54l15\xiao_nrf54l15_common.dtsi:154 */
					zephyr,oversampling = < 0x8 >;         /* in ..\platforms\Seeed Studio\zephyr\boards\arm\xiao_nrf54l15\xiao_nrf54l15_common.dtsi:155 */
				};

				/* node '/soc/peripheral@50000000/adc@d5000/channel@7' defined in ..\platforms\Seeed Studio\zephyr\boards\arm\xiao_nrf54l15\xiao_nrf54l15_common.dtsi:158 */
				channel@7 {
					reg = < 0x7 >;                         /* in ..\platforms\Seeed Studio\zephyr\boards\arm\xiao_nrf54l15\xiao_nrf54l15_common.dtsi:159 */
					zephyr,gain = "ADC_GAIN_1_4";          /* in ..\platforms\Seeed Studio\zephyr\boards\arm\xiao_nrf54l15\xiao_nrf54l15_common.dtsi:160 */
					zephyr,reference = "ADC_REF_INTERNAL"; /* in ..\platforms\Seeed Studio\zephyr\boards\arm\xiao_nrf54l15\xiao_nrf54l15_common.dtsi:161 */
					zephyr,acquisition-time = < 0x0 >;     /* in ..\platforms\Seeed Studio\zephyr\boards\arm\xiao_nrf54l15\xiao_nrf54l15_common.dtsi:162 */
					zephyr,input-positive = < 0x8 >;       /* in ..\platforms\Seeed Studio\zephyr\boards\arm\xiao_nrf54l15\xiao_nrf54l15_common.dtsi:163 */
					zephyr,resolution = < 0xc >;           /* in ..\platforms\Seeed Studio\zephyr\boards\arm\xiao_nrf54l15\xiao_nrf54l15_common.dtsi:164 */
					zephyr,oversampling = < 0x8 >;         /* in ..\platforms\Seeed Studio\zephyr\boards\arm\xiao_nrf54l15\xiao_nrf54l15_common.dtsi:165 */
				};
			};

			/* node '/soc/peripheral@50000000/nfct@d6000' defined in framework-zephyr\dts\vendor\nordic\nrf54l_05_10_15.dtsi:510 */
			nfct: nfct@d6000 {
				compatible = "nordic,nrf-nfct"; /* in framework-zephyr\dts\vendor\nordic\nrf54l_05_10_15.dtsi:511 */
				reg = < 0xd6000 0x1000 >;       /* in framework-zephyr\dts\vendor\nordic\nrf54l_05_10_15.dtsi:512 */
				interrupts = < 0xd6 0x1 >;      /* in framework-zephyr\dts\vendor\nordic\nrf54l_05_10_15.dtsi:513 */
				status = "okay";                /* in ..\platforms\Seeed Studio\zephyr\boards\arm\xiao_nrf54l15\xiao_nrf54l15_nrf54l15_cpuapp.dts:171 */
			};

			/* node '/soc/peripheral@50000000/temp@d7000' defined in framework-zephyr\dts\vendor\nordic\nrf54l_05_10_15.dtsi:517 */
			temp: temp@d7000 {
				compatible = "nordic,nrf-temp"; /* in framework-zephyr\dts\vendor\nordic\nrf54l_05_10_15.dtsi:518 */
				reg = < 0xd7000 0x1000 >;       /* in framework-zephyr\dts\vendor\nordic\nrf54l_05_10_15.dtsi:519 */
				interrupts = < 0xd7 0x1 >;      /* in framework-zephyr\dts\vendor\nordic\nrf54l_05_10_15.dtsi:520 */
				status = "okay";                /* in ..\platforms\Seeed Studio\zephyr\boards\arm\xiao_nrf54l15\xiao_nrf54l15_nrf54l15_cpuapp.dts:163 */
			};

			/* node '/soc/peripheral@50000000/gpio@d8200' defined in framework-zephyr\dts\vendor\nordic\nrf54l_05_10_15.dtsi:524 */
			gpio1: gpio@d8200 {
				compatible = "nordic,nrf-gpio";  /* in framework-zephyr\dts\vendor\nordic\nrf54l_05_10_15.dtsi:525 */
				gpio-controller;                 /* in framework-zephyr\dts\vendor\nordic\nrf54l_05_10_15.dtsi:526 */
				reg = < 0xd8200 0x300 >;         /* in framework-zephyr\dts\vendor\nordic\nrf54l_05_10_15.dtsi:527 */
				#gpio-cells = < 0x2 >;           /* in framework-zephyr\dts\vendor\nordic\nrf54l_05_10_15.dtsi:528 */
				ngpios = < 0x10 >;               /* in framework-zephyr\dts\vendor\nordic\nrf54l_05_10_15.dtsi:529 */
				port = < 0x1 >;                  /* in framework-zephyr\dts\vendor\nordic\nrf54l_05_10_15.dtsi:531 */
				gpiote-instance = < &gpiote20 >; /* in framework-zephyr\dts\vendor\nordic\nrf54l_05_10_15.dtsi:532 */
				status = "okay";                 /* in ..\platforms\Seeed Studio\zephyr\boards\arm\xiao_nrf54l15\xiao_nrf54l15_nrf54l15_cpuapp.dts:121 */
				phandle = < 0x16 >;              /* in ..\platforms\Seeed Studio\zephyr\boards\arm\xiao_nrf54l15\seeed_xiao_connector.dtsi:11 */
			};

			/* node '/soc/peripheral@50000000/gpiote@da000' defined in framework-zephyr\dts\vendor\nordic\nrf54l_05_10_15.dtsi:535 */
			gpiote20: gpiote@da000 {
				compatible = "nordic,nrf-gpiote"; /* in framework-zephyr\dts\vendor\nordic\nrf54l_05_10_15.dtsi:536 */
				reg = < 0xda000 0x1000 >;         /* in framework-zephyr\dts\vendor\nordic\nrf54l_05_10_15.dtsi:537 */
				instance = < 0x14 >;              /* in framework-zephyr\dts\vendor\nordic\nrf54l_05_10_15.dtsi:539 */
				interrupts = < 0xdb 0x1 >;        /* in framework-zephyr\dts\arm\nordic\nrf54l_05_10_15_cpuapp.dtsi:82 */
				status = "okay";                  /* in ..\platforms\Seeed Studio\zephyr\boards\arm\xiao_nrf54l15\xiao_nrf54l15_nrf54l15_cpuapp.dts:129 */
				phandle = < 0xf >;                /* in framework-zephyr\dts\vendor\nordic\nrf54l_05_10_15.dtsi:532 */
			};

			/* node '/soc/peripheral@50000000/i2s@dd000' defined in framework-zephyr\dts\vendor\nordic\nrf54l_05_10_15.dtsi:542 */
			i2s20: i2s@dd000 {
				compatible = "nordic,nrf-i2s"; /* in framework-zephyr\dts\vendor\nordic\nrf54l_05_10_15.dtsi:543 */
				#address-cells = < 0x1 >;      /* in framework-zephyr\dts\vendor\nordic\nrf54l_05_10_15.dtsi:544 */
				#size-cells = < 0x0 >;         /* in framework-zephyr\dts\vendor\nordic\nrf54l_05_10_15.dtsi:545 */
				reg = < 0xdd000 0x1000 >;      /* in framework-zephyr\dts\vendor\nordic\nrf54l_05_10_15.dtsi:546 */
				interrupts = < 0xdd 0x1 >;     /* in framework-zephyr\dts\vendor\nordic\nrf54l_05_10_15.dtsi:547 */
				status = "disabled";           /* in framework-zephyr\dts\vendor\nordic\nrf54l_05_10_15.dtsi:548 */
			};

			/* node '/soc/peripheral@50000000/qdec@e0000' defined in framework-zephyr\dts\vendor\nordic\nrf54l_05_10_15.dtsi:551 */
			qdec20: qdec@e0000 {
				compatible = "nordic,nrf-qdec"; /* in framework-zephyr\dts\vendor\nordic\nrf54l_05_10_15.dtsi:552 */
				reg = < 0xe0000 0x1000 >;       /* in framework-zephyr\dts\vendor\nordic\nrf54l_05_10_15.dtsi:553 */
				interrupts = < 0xe0 0x1 >;      /* in framework-zephyr\dts\vendor\nordic\nrf54l_05_10_15.dtsi:554 */
				status = "disabled";            /* in framework-zephyr\dts\vendor\nordic\nrf54l_05_10_15.dtsi:555 */
			};

			/* node '/soc/peripheral@50000000/qdec@e1000' defined in framework-zephyr\dts\vendor\nordic\nrf54l_05_10_15.dtsi:558 */
			qdec21: qdec@e1000 {
				compatible = "nordic,nrf-qdec"; /* in framework-zephyr\dts\vendor\nordic\nrf54l_05_10_15.dtsi:559 */
				reg = < 0xe1000 0x1000 >;       /* in framework-zephyr\dts\vendor\nordic\nrf54l_05_10_15.dtsi:560 */
				interrupts = < 0xe1 0x1 >;      /* in framework-zephyr\dts\vendor\nordic\nrf54l_05_10_15.dtsi:561 */
				status = "disabled";            /* in framework-zephyr\dts\vendor\nordic\nrf54l_05_10_15.dtsi:562 */
			};

			/* node '/soc/peripheral@50000000/grtc@e2000' defined in framework-zephyr\dts\vendor\nordic\nrf54l_05_10_15.dtsi:565 */
			grtc: grtc@e2000 {
				compatible = "nordic,nrf-grtc";                                       /* in framework-zephyr\dts\vendor\nordic\nrf54l_05_10_15.dtsi:566 */
				reg = < 0xe2000 0x1000 >;                                             /* in framework-zephyr\dts\vendor\nordic\nrf54l_05_10_15.dtsi:567 */
				cc-num = < 0xc >;                                                     /* in framework-zephyr\dts\vendor\nordic\nrf54l_05_10_15.dtsi:568 */
				clocks = < &lfxo >,
				         < &pclk >;                                                   /* in framework-zephyr\dts\vendor\nordic\nrf54l_05_10_15.dtsi:569 */
				clock-names = "lfclock",
				              "hfclock";                                              /* in framework-zephyr\dts\vendor\nordic\nrf54l_05_10_15.dtsi:570 */
				interrupts = < 0xe4 0x1 >,
				             < 0xe5 0x1 >;                                            /* in framework-zephyr\dts\arm\nordic\nrf54l_05_10_15_cpuapp.dtsi:73 */
				owned-channels = < 0x0 0x1 0x2 0x3 0x4 0x5 0x6 0x7 0x8 0x9 0xa 0xb >; /* in ..\platforms\Seeed Studio\zephyr\boards\arm\xiao_nrf54l15\xiao_nrf54l15_nrf54l15_cpuapp.dts:65 */
				child-owned-channels = < 0x3 0x4 0x7 0x8 0x9 0xa 0xb >;               /* in ..\platforms\Seeed Studio\zephyr\boards\arm\xiao_nrf54l15\xiao_nrf54l15_nrf54l15_cpuapp.dts:67 */
				status = "okay";                                                      /* in ..\platforms\Seeed Studio\zephyr\boards\arm\xiao_nrf54l15\xiao_nrf54l15_nrf54l15_cpuapp.dts:68 */
			};

			/* node '/soc/peripheral@50000000/dppic@102000' defined in framework-zephyr\dts\vendor\nordic\nrf54l_05_10_15.dtsi:574 */
			dppic30: dppic@102000 {
				compatible = "nordic,nrf-dppic"; /* in framework-zephyr\dts\vendor\nordic\nrf54l_05_10_15.dtsi:575 */
				reg = < 0x102000 0x808 >;        /* in framework-zephyr\dts\vendor\nordic\nrf54l_05_10_15.dtsi:576 */
				status = "okay";                 /* in framework-zephyr\dts\arm\nordic\nrf54l_05_10_15_cpuapp.dtsi:107 */
			};

			/* node '/soc/peripheral@50000000/ppib@103000' defined in framework-zephyr\dts\vendor\nordic\nrf54l_05_10_15.dtsi:580 */
			ppib30: ppib@103000 {
				compatible = "nordic,nrf-ppib"; /* in framework-zephyr\dts\vendor\nordic\nrf54l_05_10_15.dtsi:581 */
				reg = < 0x103000 0x1000 >;      /* in framework-zephyr\dts\vendor\nordic\nrf54l_05_10_15.dtsi:582 */
				status = "okay";                /* in framework-zephyr\dts\arm\nordic\nrf54l_05_10_15_cpuapp.dtsi:139 */
			};

			/* node '/soc/peripheral@50000000/i2c@104000' defined in framework-zephyr\dts\vendor\nordic\nrf54l_05_10_15.dtsi:586 */
			i2c30: i2c@104000 {
				compatible = "nordic,nrf-twim"; /* in framework-zephyr\dts\vendor\nordic\nrf54l_05_10_15.dtsi:587 */
				#address-cells = < 0x1 >;       /* in framework-zephyr\dts\vendor\nordic\nrf54l_05_10_15.dtsi:588 */
				#size-cells = < 0x0 >;          /* in framework-zephyr\dts\vendor\nordic\nrf54l_05_10_15.dtsi:589 */
				reg = < 0x104000 0x1000 >;      /* in framework-zephyr\dts\vendor\nordic\nrf54l_05_10_15.dtsi:590 */
				interrupts = < 0x104 0x1 >;     /* in framework-zephyr\dts\vendor\nordic\nrf54l_05_10_15.dtsi:591 */
				easydma-maxcnt-bits = < 0x10 >; /* in framework-zephyr\dts\vendor\nordic\nrf54l_05_10_15.dtsi:592 */
				zephyr,pm-device-runtime-auto;  /* in framework-zephyr\dts\vendor\nordic\nrf54l_05_10_15.dtsi:594 */
				pinctrl-0 = < &i2c30_default >; /* in ..\platforms\Seeed Studio\zephyr\boards\arm\xiao_nrf54l15\xiao_nrf54l15_common.dtsi:59 */
				pinctrl-1 = < &i2c30_sleep >;   /* in ..\platforms\Seeed Studio\zephyr\boards\arm\xiao_nrf54l15\xiao_nrf54l15_common.dtsi:60 */
				pinctrl-names = "default",
				                "sleep";        /* in ..\platforms\Seeed Studio\zephyr\boards\arm\xiao_nrf54l15\xiao_nrf54l15_common.dtsi:61 */
				clock-frequency = < 0x61a80 >;  /* in ..\platforms\Seeed Studio\zephyr\boards\arm\xiao_nrf54l15\xiao_nrf54l15_common.dtsi:62 */
				status = "okay";                /* in ..\platforms\Seeed Studio\zephyr\boards\arm\xiao_nrf54l15\xiao_nrf54l15_nrf54l15_cpuapp.dts:88 */

				/* node '/soc/peripheral@50000000/i2c@104000/lsm6ds3tr-c@6a' defined in ..\platforms\Seeed Studio\zephyr\boards\arm\xiao_nrf54l15\xiao_nrf54l15_nrf54l15_cpuapp.dts:90 */
				lsm6ds3tr_c: lsm6ds3tr-c@6a {
					compatible = "st,lsm6dsl";      /* in ..\platforms\Seeed Studio\zephyr\boards\arm\xiao_nrf54l15\xiao_nrf54l15_nrf54l15_cpuapp.dts:91 */
					reg = < 0x6a >;                 /* in ..\platforms\Seeed Studio\zephyr\boards\arm\xiao_nrf54l15\xiao_nrf54l15_nrf54l15_cpuapp.dts:92 */
					irq-gpios = < &gpio0 0x2 0x0 >; /* in ..\platforms\Seeed Studio\zephyr\boards\arm\xiao_nrf54l15\xiao_nrf54l15_nrf54l15_cpuapp.dts:93 */
					status = "okay";                /* in ..\platforms\Seeed Studio\zephyr\boards\arm\xiao_nrf54l15\xiao_nrf54l15_nrf54l15_cpuapp.dts:94 */
				};
			};

			/* node '/soc/peripheral@50000000/spi@104000' defined in framework-zephyr\dts\vendor\nordic\nrf54l_05_10_15.dtsi:597 */
			spi30: spi@104000 {
				compatible = "nordic,nrf-spim"; /* in framework-zephyr\dts\vendor\nordic\nrf54l_05_10_15.dtsi:604 */
				#address-cells = < 0x1 >;       /* in framework-zephyr\dts\vendor\nordic\nrf54l_05_10_15.dtsi:605 */
				#size-cells = < 0x0 >;          /* in framework-zephyr\dts\vendor\nordic\nrf54l_05_10_15.dtsi:606 */
				reg = < 0x104000 0x1000 >;      /* in framework-zephyr\dts\vendor\nordic\nrf54l_05_10_15.dtsi:607 */
				interrupts = < 0x104 0x1 >;     /* in framework-zephyr\dts\vendor\nordic\nrf54l_05_10_15.dtsi:608 */
				max-frequency = < 0x7a1200 >;   /* in framework-zephyr\dts\vendor\nordic\nrf54l_05_10_15.dtsi:609 */
				easydma-maxcnt-bits = < 0x10 >; /* in framework-zephyr\dts\vendor\nordic\nrf54l_05_10_15.dtsi:610 */
				rx-delay-supported;             /* in framework-zephyr\dts\vendor\nordic\nrf54l_05_10_15.dtsi:611 */
				rx-delay = < 0x1 >;             /* in framework-zephyr\dts\vendor\nordic\nrf54l_05_10_15.dtsi:612 */
				status = "disabled";            /* in framework-zephyr\dts\vendor\nordic\nrf54l_05_10_15.dtsi:613 */
			};

			/* node '/soc/peripheral@50000000/uart@104000' defined in framework-zephyr\dts\vendor\nordic\nrf54l_05_10_15.dtsi:616 */
			uart30: uart@104000 {
				compatible = "nordic,nrf-uarte"; /* in framework-zephyr\dts\vendor\nordic\nrf54l_05_10_15.dtsi:617 */
				reg = < 0x104000 0x1000 >;       /* in framework-zephyr\dts\vendor\nordic\nrf54l_05_10_15.dtsi:618 */
				interrupts = < 0x104 0x1 >;      /* in framework-zephyr\dts\vendor\nordic\nrf54l_05_10_15.dtsi:619 */
				status = "disabled";             /* in framework-zephyr\dts\vendor\nordic\nrf54l_05_10_15.dtsi:620 */
				endtx-stoptx-supported;          /* in framework-zephyr\dts\vendor\nordic\nrf54l_05_10_15.dtsi:621 */
				frame-timeout-supported;         /* in framework-zephyr\dts\vendor\nordic\nrf54l_05_10_15.dtsi:622 */
			};

			/* node '/soc/peripheral@50000000/clock@10e000' defined in framework-zephyr\dts\vendor\nordic\nrf54l_05_10_15.dtsi:625 */
			clock: clock@10e000 {
				compatible = "nordic,nrf-clock"; /* in framework-zephyr\dts\vendor\nordic\nrf54l_05_10_15.dtsi:626 */
				reg = < 0x10e000 0x1000 >;       /* in framework-zephyr\dts\vendor\nordic\nrf54l_05_10_15.dtsi:627 */
				interrupts = < 0x105 0x1 >;      /* in framework-zephyr\dts\vendor\nordic\nrf54l_05_10_15.dtsi:628 */
				status = "okay";                 /* in ..\platforms\Seeed Studio\zephyr\boards\arm\xiao_nrf54l15\xiao_nrf54l15_nrf54l15_cpuapp.dts:175 */
			};

			/* node '/soc/peripheral@50000000/power@10e000' defined in framework-zephyr\dts\vendor\nordic\nrf54l_05_10_15.dtsi:632 */
			power: power@10e000 {
				compatible = "nordic,nrf-power";  /* in framework-zephyr\dts\vendor\nordic\nrf54l_05_10_15.dtsi:633 */
				reg = < 0x10e000 0x1000 >;        /* in framework-zephyr\dts\vendor\nordic\nrf54l_05_10_15.dtsi:634 */
				ranges = < 0x0 0x10e000 0x1000 >; /* in framework-zephyr\dts\vendor\nordic\nrf54l_05_10_15.dtsi:635 */
				interrupts = < 0x105 0x1 >;       /* in framework-zephyr\dts\vendor\nordic\nrf54l_05_10_15.dtsi:636 */
				status = "disabled";              /* in framework-zephyr\dts\vendor\nordic\nrf54l_05_10_15.dtsi:637 */
				#address-cells = < 0x1 >;         /* in framework-zephyr\dts\vendor\nordic\nrf54l_05_10_15.dtsi:638 */
				#size-cells = < 0x1 >;            /* in framework-zephyr\dts\vendor\nordic\nrf54l_05_10_15.dtsi:639 */

				/* node '/soc/peripheral@50000000/power@10e000/gpregret1@500' defined in framework-zephyr\dts\vendor\nordic\nrf54l_05_10_15.dtsi:641 */
				gpregret1: gpregret1@500 {
					#address-cells = < 0x1 >;           /* in framework-zephyr\dts\vendor\nordic\nrf54l_05_10_15.dtsi:642 */
					#size-cells = < 0x1 >;              /* in framework-zephyr\dts\vendor\nordic\nrf54l_05_10_15.dtsi:643 */
					compatible = "nordic,nrf-gpregret"; /* in framework-zephyr\dts\vendor\nordic\nrf54l_05_10_15.dtsi:644 */
					reg = < 0x500 0x1 >;                /* in framework-zephyr\dts\vendor\nordic\nrf54l_05_10_15.dtsi:645 */
					status = "disabled";                /* in framework-zephyr\dts\vendor\nordic\nrf54l_05_10_15.dtsi:646 */
				};

				/* node '/soc/peripheral@50000000/power@10e000/gpregret2@504' defined in framework-zephyr\dts\vendor\nordic\nrf54l_05_10_15.dtsi:649 */
				gpregret2: gpregret2@504 {
					#address-cells = < 0x1 >;           /* in framework-zephyr\dts\vendor\nordic\nrf54l_05_10_15.dtsi:650 */
					#size-cells = < 0x1 >;              /* in framework-zephyr\dts\vendor\nordic\nrf54l_05_10_15.dtsi:651 */
					compatible = "nordic,nrf-gpregret"; /* in framework-zephyr\dts\vendor\nordic\nrf54l_05_10_15.dtsi:652 */
					reg = < 0x504 0x1 >;                /* in framework-zephyr\dts\vendor\nordic\nrf54l_05_10_15.dtsi:653 */
					status = "disabled";                /* in framework-zephyr\dts\vendor\nordic\nrf54l_05_10_15.dtsi:654 */
				};
			};

			/* node '/soc/peripheral@50000000/comparator@106000' defined in framework-zephyr\dts\vendor\nordic\nrf54l_05_10_15.dtsi:658 */
			comp: comparator@106000 {
				compatible = "nordic,nrf-comp"; /* in framework-zephyr\dts\vendor\nordic\nrf54l_05_10_15.dtsi:663 */
				reg = < 0x106000 0x1000 >;      /* in framework-zephyr\dts\vendor\nordic\nrf54l_05_10_15.dtsi:664 */
				status = "disabled";            /* in framework-zephyr\dts\vendor\nordic\nrf54l_05_10_15.dtsi:665 */
				interrupts = < 0x106 0x1 >;     /* in framework-zephyr\dts\vendor\nordic\nrf54l_05_10_15.dtsi:666 */
			};

			/* node '/soc/peripheral@50000000/watchdog@108000' defined in framework-zephyr\dts\vendor\nordic\nrf54l_05_10_15.dtsi:672 */
			wdt30: watchdog@108000 {
				compatible = "nordic,nrf-wdt"; /* in framework-zephyr\dts\vendor\nordic\nrf54l_05_10_15.dtsi:673 */
				reg = < 0x108000 0x620 >;      /* in framework-zephyr\dts\vendor\nordic\nrf54l_05_10_15.dtsi:674 */
				interrupts = < 0x108 0x1 >;    /* in framework-zephyr\dts\vendor\nordic\nrf54l_05_10_15.dtsi:675 */
				status = "disabled";           /* in framework-zephyr\dts\vendor\nordic\nrf54l_05_10_15.dtsi:676 */
			};

			/* node '/soc/peripheral@50000000/watchdog@109000' defined in framework-zephyr\dts\vendor\nordic\nrf54l_05_10_15.dtsi:680 */
			wdt31: watchdog@109000 {
				compatible = "nordic,nrf-wdt"; /* in framework-zephyr\dts\vendor\nordic\nrf54l_05_10_15.dtsi:681 */
				reg = < 0x109000 0x620 >;      /* in framework-zephyr\dts\vendor\nordic\nrf54l_05_10_15.dtsi:682 */
				interrupts = < 0x109 0x1 >;    /* in framework-zephyr\dts\vendor\nordic\nrf54l_05_10_15.dtsi:683 */
				status = "disabled";           /* in framework-zephyr\dts\vendor\nordic\nrf54l_05_10_15.dtsi:684 */
			};

			/* node '/soc/peripheral@50000000/gpio@10a000' defined in framework-zephyr\dts\vendor\nordic\nrf54l_05_10_15.dtsi:687 */
			gpio0: gpio@10a000 {
				compatible = "nordic,nrf-gpio";  /* in framework-zephyr\dts\vendor\nordic\nrf54l_05_10_15.dtsi:688 */
				gpio-controller;                 /* in framework-zephyr\dts\vendor\nordic\nrf54l_05_10_15.dtsi:689 */
				reg = < 0x10a000 0x300 >;        /* in framework-zephyr\dts\vendor\nordic\nrf54l_05_10_15.dtsi:690 */
				#gpio-cells = < 0x2 >;           /* in framework-zephyr\dts\vendor\nordic\nrf54l_05_10_15.dtsi:691 */
				ngpios = < 0x5 >;                /* in framework-zephyr\dts\vendor\nordic\nrf54l_05_10_15.dtsi:692 */
				port = < 0x0 >;                  /* in framework-zephyr\dts\vendor\nordic\nrf54l_05_10_15.dtsi:694 */
				gpiote-instance = < &gpiote30 >; /* in framework-zephyr\dts\vendor\nordic\nrf54l_05_10_15.dtsi:695 */
				status = "okay";                 /* in ..\platforms\Seeed Studio\zephyr\boards\arm\xiao_nrf54l15\xiao_nrf54l15_nrf54l15_cpuapp.dts:111 */
				phandle = < 0x14 >;              /* in ..\platforms\Seeed Studio\zephyr\boards\arm\xiao_nrf54l15\xiao_nrf54l15_nrf54l15_cpuapp.dts:93 */

				/* node '/soc/peripheral@50000000/gpio@10a000/imu_power_default_on' defined in ..\platforms\Seeed Studio\zephyr\boards\arm\xiao_nrf54l15\xiao_nrf54l15_nrf54l15_cpuapp.dts:113 */
				imu_power_default_on: imu_power_default_on {
					gpio-hog;                       /* in ..\platforms\Seeed Studio\zephyr\boards\arm\xiao_nrf54l15\xiao_nrf54l15_nrf54l15_cpuapp.dts:114 */
					gpios = < 0x1 0x0 >;            /* in ..\platforms\Seeed Studio\zephyr\boards\arm\xiao_nrf54l15\xiao_nrf54l15_nrf54l15_cpuapp.dts:115 */
					line-name = "imu-power-enable"; /* in ..\platforms\Seeed Studio\zephyr\boards\arm\xiao_nrf54l15\xiao_nrf54l15_nrf54l15_cpuapp.dts:116 */
				};
			};

			/* node '/soc/peripheral@50000000/gpiote@10c000' defined in framework-zephyr\dts\vendor\nordic\nrf54l_05_10_15.dtsi:698 */
			gpiote30: gpiote@10c000 {
				compatible = "nordic,nrf-gpiote"; /* in framework-zephyr\dts\vendor\nordic\nrf54l_05_10_15.dtsi:699 */
				reg = < 0x10c000 0x1000 >;        /* in framework-zephyr\dts\vendor\nordic\nrf54l_05_10_15.dtsi:700 */
				instance = < 0x1e >;              /* in framework-zephyr\dts\vendor\nordic\nrf54l_05_10_15.dtsi:702 */
				interrupts = < 0x10d 0x1 >;       /* in framework-zephyr\dts\arm\nordic\nrf54l_05_10_15_cpuapp.dtsi:90 */
				status = "okay";                  /* in ..\platforms\Seeed Studio\zephyr\boards\arm\xiao_nrf54l15\xiao_nrf54l15_nrf54l15_cpuapp.dts:133 */
				phandle = < 0x15 >;               /* in framework-zephyr\dts\vendor\nordic\nrf54l_05_10_15.dtsi:695 */
			};

			/* node '/soc/peripheral@50000000/regulator@120000' defined in framework-zephyr\dts\vendor\nordic\nrf54l_05_10_15.dtsi:705 */
			regulators: regulator@120000 {
				compatible = "nordic,nrf54l-regulators"; /* in framework-zephyr\dts\vendor\nordic\nrf54l_05_10_15.dtsi:706 */
				reg = < 0x120000 0x1000 >;               /* in framework-zephyr\dts\vendor\nordic\nrf54l_05_10_15.dtsi:707 */
				#address-cells = < 0x1 >;                /* in framework-zephyr\dts\vendor\nordic\nrf54l_05_10_15.dtsi:709 */
				#size-cells = < 0x1 >;                   /* in framework-zephyr\dts\vendor\nordic\nrf54l_05_10_15.dtsi:710 */
				status = "okay";                         /* in ..\platforms\Seeed Studio\zephyr\boards\arm\xiao_nrf54l15\xiao_nrf54l15_nrf54l15_cpuapp.dts:137 */

				/* node '/soc/peripheral@50000000/regulator@120000/regulator@120600' defined in framework-zephyr\dts\vendor\nordic\nrf54l_05_10_15.dtsi:712 */
				vregmain: regulator@120600 {
					compatible = "nordic,nrf5x-regulator"; /* in framework-zephyr\dts\vendor\nordic\nrf54l_05_10_15.dtsi:713 */
					reg = < 0x120600 0x1 >;                /* in framework-zephyr\dts\vendor\nordic\nrf54l_05_10_15.dtsi:714 */
					regulator-name = "VREGMAIN";           /* in framework-zephyr\dts\vendor\nordic\nrf54l_05_10_15.dtsi:716 */
					status = "okay";                       /* in ..\platforms\Seeed Studio\zephyr\boards\arm\xiao_nrf54l15\xiao_nrf54l15_nrf54l15_cpuapp.dts:141 */
					regulator-initial-mode = < 0x1 >;      /* in ..\platforms\Seeed Studio\zephyr\boards\arm\xiao_nrf54l15\xiao_nrf54l15_nrf54l15_cpuapp.dts:142 */
				};
			};
		};

		/* node '/soc/rram-controller@5004b000' defined in framework-zephyr\dts\vendor\nordic\nrf54l_05_10_15.dtsi:722 */
		rram_controller: rram-controller@5004b000 {
			compatible = "nordic,rram-controller"; /* in framework-zephyr\dts\vendor\nordic\nrf54l_05_10_15.dtsi:723 */
			reg = < 0x5004b000 0x1000 >;           /* in framework-zephyr\dts\vendor\nordic\nrf54l_05_10_15.dtsi:724 */
			#address-cells = < 0x1 >;              /* in framework-zephyr\dts\vendor\nordic\nrf54l_05_10_15.dtsi:725 */
			#size-cells = < 0x1 >;                 /* in framework-zephyr\dts\vendor\nordic\nrf54l_05_10_15.dtsi:726 */
			interrupts = < 0x4b 0x1 >;             /* in framework-zephyr\dts\vendor\nordic\nrf54l_05_10_15.dtsi:727 */

			/* node '/soc/rram-controller@5004b000/rram@0' defined in framework-zephyr\dts\vendor\nordic\nrf54l_05_10_15.dtsi:729 */
			cpuapp_rram: rram@0 {
				compatible = "soc-nv-flash";   /* in framework-zephyr\dts\vendor\nordic\nrf54l_05_10_15.dtsi:730 */
				erase-block-size = < 0x1000 >; /* in framework-zephyr\dts\vendor\nordic\nrf54l_05_10_15.dtsi:731 */
				write-block-size = < 0x10 >;   /* in framework-zephyr\dts\vendor\nordic\nrf54l_05_10_15.dtsi:732 */
				reg = < 0x0 0x165000 >;        /* in framework-zephyr\dts\vendor\nordic\nrf54l15.dtsi:28 */

				/* node '/soc/rram-controller@5004b000/rram@0/partitions' defined in ..\platforms\Seeed Studio\zephyr\boards\arm\xiao_nrf54l15\xiao_nrf54l15_nrf54l15_cpuapp.dts:180 */
				partitions {
					compatible = "fixed-partitions"; /* in ..\platforms\Seeed Studio\zephyr\boards\arm\xiao_nrf54l15\xiao_nrf54l15_nrf54l15_cpuapp.dts:181 */
					#address-cells = < 0x1 >;        /* in ..\platforms\Seeed Studio\zephyr\boards\arm\xiao_nrf54l15\xiao_nrf54l15_nrf54l15_cpuapp.dts:182 */
					#size-cells = < 0x1 >;           /* in ..\platforms\Seeed Studio\zephyr\boards\arm\xiao_nrf54l15\xiao_nrf54l15_nrf54l15_cpuapp.dts:183 */

					/* node '/soc/rram-controller@5004b000/rram@0/partitions/partition@0' defined in ..\platforms\Seeed Studio\zephyr\boards\arm\xiao_nrf54l15\xiao_nrf54l15_nrf54l15_cpuapp.dts:185 */
					boot_partition: partition@0 {
						label = "mcuboot";     /* in ..\platforms\Seeed Studio\zephyr\boards\arm\xiao_nrf54l15\xiao_nrf54l15_nrf54l15_cpuapp.dts:186 */
						reg = < 0x0 0x10000 >; /* in ..\platforms\Seeed Studio\zephyr\boards\arm\xiao_nrf54l15\xiao_nrf54l15_nrf54l15_cpuapp.dts:187 */
					};

					/* node '/soc/rram-controller@5004b000/rram@0/partitions/partition@10000' defined in ..\platforms\Seeed Studio\zephyr\boards\arm\xiao_nrf54l15\xiao_nrf54l15_nrf54l15_cpuapp.dts:190 */
					slot0_partition: partition@10000 {
						label = "image-0";         /* in ..\platforms\Seeed Studio\zephyr\boards\arm\xiao_nrf54l15\xiao_nrf54l15_nrf54l15_cpuapp.dts:191 */
						reg = < 0x10000 0xa6000 >; /* in ..\platforms\Seeed Studio\zephyr\boards\arm\xiao_nrf54l15\xiao_nrf54l15_nrf54l15_cpuapp.dts:192 */
					};

					/* node '/soc/rram-controller@5004b000/rram@0/partitions/partition@b6000' defined in ..\platforms\Seeed Studio\zephyr\boards\arm\xiao_nrf54l15\xiao_nrf54l15_nrf54l15_cpuapp.dts:195 */
					slot1_partition: partition@b6000 {
						label = "image-1";         /* in ..\platforms\Seeed Studio\zephyr\boards\arm\xiao_nrf54l15\xiao_nrf54l15_nrf54l15_cpuapp.dts:196 */
						reg = < 0xb6000 0xa6000 >; /* in ..\platforms\Seeed Studio\zephyr\boards\arm\xiao_nrf54l15\xiao_nrf54l15_nrf54l15_cpuapp.dts:197 */
					};

					/* node '/soc/rram-controller@5004b000/rram@0/partitions/partition@15c000' defined in ..\platforms\Seeed Studio\zephyr\boards\arm\xiao_nrf54l15\xiao_nrf54l15_nrf54l15_cpuapp.dts:200 */
					storage_partition: partition@15c000 {
						label = "storage";         /* in ..\platforms\Seeed Studio\zephyr\boards\arm\xiao_nrf54l15\xiao_nrf54l15_nrf54l15_cpuapp.dts:201 */
						reg = < 0x15c000 0x9000 >; /* in ..\platforms\Seeed Studio\zephyr\boards\arm\xiao_nrf54l15\xiao_nrf54l15_nrf54l15_cpuapp.dts:202 */
					};
				};
			};
		};

		/* node '/soc/memory@50041000' defined in framework-zephyr\dts\vendor\nordic\nrf54l_05_10_15.dtsi:736 */
		nrf_mpc: memory@50041000 {
			compatible = "nordic,nrf-mpc";     /* in framework-zephyr\dts\vendor\nordic\nrf54l_05_10_15.dtsi:737 */
			reg = < 0x50041000 0x1000 >;       /* in framework-zephyr\dts\vendor\nordic\nrf54l_05_10_15.dtsi:738 */
			#address-cells = < 0x1 >;          /* in framework-zephyr\dts\vendor\nordic\nrf54l_05_10_15.dtsi:739 */
			#size-cells = < 0x1 >;             /* in framework-zephyr\dts\vendor\nordic\nrf54l_05_10_15.dtsi:740 */
			override-num = < 0x5 >;            /* in framework-zephyr\dts\vendor\nordic\nrf54l_05_10_15.dtsi:741 */
			override-granularity = < 0x1000 >; /* in framework-zephyr\dts\vendor\nordic\nrf54l_05_10_15.dtsi:742 */
		};

		/* node '/soc/cpuapp-ppb-bus' defined in framework-zephyr\dts\vendor\nordic\nrf54l_05_10_15.dtsi:745 */
		cpuapp_ppb: cpuapp-ppb-bus {
			#address-cells = < 0x1 >;  /* in framework-zephyr\dts\vendor\nordic\nrf54l_05_10_15.dtsi:746 */
			#size-cells = < 0x1 >;     /* in framework-zephyr\dts\vendor\nordic\nrf54l_05_10_15.dtsi:747 */
			compatible = "simple-bus"; /* in framework-zephyr\dts\arm\nordic\nrf54l_05_10_15_cpuapp.dtsi:65 */
			ranges;                    /* in framework-zephyr\dts\arm\nordic\nrf54l_05_10_15_cpuapp.dtsi:66 */

			/* node '/soc/cpuapp-ppb-bus/interrupt-controller@e000e100' defined in framework-zephyr\dts\vendor\nordic\nrf54l_05_10_15.dtsi:749 */
			cpuapp_nvic: nvic: interrupt-controller@e000e100 {
				#address-cells = < 0x1 >;            /* in framework-zephyr\dts\vendor\nordic\nrf54l_05_10_15.dtsi:750 */
				compatible = "arm,v8m-nvic";         /* in framework-zephyr\dts\vendor\nordic\nrf54l_05_10_15.dtsi:751 */
				reg = < 0xe000e100 0xc00 >;          /* in framework-zephyr\dts\vendor\nordic\nrf54l_05_10_15.dtsi:752 */
				arm,num-irq-priority-bits = < 0x3 >; /* in framework-zephyr\dts\vendor\nordic\nrf54l_05_10_15.dtsi:753 */
				interrupt-controller;                /* in framework-zephyr\dts\vendor\nordic\nrf54l_05_10_15.dtsi:754 */
				#interrupt-cells = < 0x2 >;          /* in framework-zephyr\dts\vendor\nordic\nrf54l_05_10_15.dtsi:755 */
				phandle = < 0x2 >;                   /* in framework-zephyr\dts\arm\nordic\nrf54l_05_10_15_cpuapp.dtsi:24 */
			};

			/* node '/soc/cpuapp-ppb-bus/timer@e000e010' defined in framework-zephyr\dts\vendor\nordic\nrf54l_05_10_15.dtsi:758 */
			cpuapp_systick: systick: timer@e000e010 {
				compatible = "arm,armv8m-systick"; /* in framework-zephyr\dts\vendor\nordic\nrf54l_05_10_15.dtsi:759 */
				reg = < 0xe000e010 0x10 >;         /* in framework-zephyr\dts\vendor\nordic\nrf54l_05_10_15.dtsi:760 */
				status = "disabled";               /* in framework-zephyr\dts\vendor\nordic\nrf54l_05_10_15.dtsi:761 */
			};
		};
	};

	/* node '/chosen' defined in framework-zephyr\dts\arm\nordic\nrf54l_05_10_15_cpuapp.dtsi:17 */
	chosen {
		zephyr,bt-hci = &bt_hci_controller;         /* in framework-zephyr\dts\arm\nordic\nrf54l_05_10_15_cpuapp.dtsi:18 */
		zephyr,entropy = &rng;                      /* in framework-zephyr\dts\arm\nordic\nrf54l_05_10_15_cpuapp.dtsi:19 */
		zephyr,code-partition = &slot0_partition;   /* in ..\platforms\Seeed Studio\zephyr\boards\arm\xiao_nrf54l15\xiao_nrf54l15_nrf54l15_cpuapp.dts:45 */
		zephyr,sram = &cpuapp_sram;                 /* in ..\platforms\Seeed Studio\zephyr\boards\arm\xiao_nrf54l15\xiao_nrf54l15_nrf54l15_cpuapp.dts:46 */
		zephyr,flash = &cpuapp_rram;                /* in ..\platforms\Seeed Studio\zephyr\boards\arm\xiao_nrf54l15\xiao_nrf54l15_nrf54l15_cpuapp.dts:47 */
		zephyr,flash-controller = &rram_controller; /* in ..\platforms\Seeed Studio\zephyr\boards\arm\xiao_nrf54l15\xiao_nrf54l15_nrf54l15_cpuapp.dts:48 */
		zephyr,console = &uart20;                   /* in ..\platforms\Seeed Studio\zephyr\boards\arm\xiao_nrf54l15\xiao_nrf54l15_nrf54l15_cpuapp.dts:49 */
		zephyr,shell-uart = &uart20;                /* in ..\platforms\Seeed Studio\zephyr\boards\arm\xiao_nrf54l15\xiao_nrf54l15_nrf54l15_cpuapp.dts:50 */
		nordic,rpc-uart = &uart20;                  /* in ..\platforms\Seeed Studio\zephyr\boards\arm\xiao_nrf54l15\xiao_nrf54l15_nrf54l15_cpuapp.dts:51 */
		zephyr,ieee802154 = &ieee802154;            /* in ..\platforms\Seeed Studio\zephyr\boards\arm\xiao_nrf54l15\xiao_nrf54l15_nrf54l15_cpuapp.dts:52 */
	};

	/* node '/rng' defined in framework-zephyr\dts\arm\nordic\nrf54l_05_10_15_cpuapp.dtsi:28 */
	rng: rng {
		status = "okay";                          /* in framework-zephyr\dts\arm\nordic\nrf54l_05_10_15_cpuapp.dtsi:29 */
		compatible = "nordic,nrf-cracen-ctrdrbg"; /* in framework-zephyr\dts\arm\nordic\nrf54l_05_10_15_cpuapp.dtsi:30 */
	};

	/* node '/psa-rng' defined in framework-zephyr\dts\arm\nordic\nrf54l_05_10_15_cpuapp.dtsi:33 */
	psa_rng: psa-rng {
		compatible = "zephyr,psa-crypto-rng"; /* in framework-zephyr\dts\arm\nordic\nrf54l_05_10_15_cpuapp.dtsi:34 */
		status = "disabled";                  /* in framework-zephyr\dts\arm\nordic\nrf54l_05_10_15_cpuapp.dtsi:35 */
	};

	/* node '/connector' defined in ..\platforms\Seeed Studio\zephyr\boards\arm\xiao_nrf54l15\seeed_xiao_connector.dtsi:6 */
	xiao_d: connector {
		compatible = "seeed,xiao-gpio";            /* in ..\platforms\Seeed Studio\zephyr\boards\arm\xiao_nrf54l15\seeed_xiao_connector.dtsi:7 */
		#gpio-cells = < 0x2 >;                     /* in ..\platforms\Seeed Studio\zephyr\boards\arm\xiao_nrf54l15\seeed_xiao_connector.dtsi:8 */
		gpio-map-mask = < 0xffffffff 0xffffffc0 >; /* in ..\platforms\Seeed Studio\zephyr\boards\arm\xiao_nrf54l15\seeed_xiao_connector.dtsi:9 */
		gpio-map-pass-thru = < 0x0 0x3f >;         /* in ..\platforms\Seeed Studio\zephyr\boards\arm\xiao_nrf54l15\seeed_xiao_connector.dtsi:10 */
		gpio-map = < 0x0 0x0 &gpio1 0x4 0x0 >,
		           < 0x1 0x0 &gpio1 0x5 0x0 >,
		           < 0x2 0x0 &gpio1 0x6 0x0 >,
		           < 0x3 0x0 &gpio1 0x7 0x0 >,
		           < 0x4 0x0 &gpio1 0xa 0x0 >,
		           < 0x5 0x0 &gpio1 0xb 0x0 >,
		           < 0x6 0x0 &gpio2 0x8 0x0 >,
		           < 0x7 0x0 &gpio2 0x7 0x0 >,
		           < 0x8 0x0 &gpio2 0x1 0x0 >,
		           < 0x9 0x0 &gpio2 0x4 0x0 >,
		           < 0xa 0x0 &gpio2 0x2 0x0 >,
		           < 0xb 0x0 &gpio0 0x3 0x0 >,
		           < 0xc 0x0 &gpio0 0x4 0x0 >,
		           < 0xd 0x0 &gpio2 0xa 0x0 >,
		           < 0xe 0x0 &gpio2 0x9 0x0 >,
		           < 0xf 0x0 &gpio2 0x6 0x0 >;     /* in ..\platforms\Seeed Studio\zephyr\boards\arm\xiao_nrf54l15\seeed_xiao_connector.dtsi:11 */
	};

	/* node '/leds' defined in ..\platforms\Seeed Studio\zephyr\boards\arm\xiao_nrf54l15\xiao_nrf54l15_common.dtsi:9 */
	leds {
		compatible = "gpio-leds"; /* in ..\platforms\Seeed Studio\zephyr\boards\arm\xiao_nrf54l15\xiao_nrf54l15_common.dtsi:10 */

		/* node '/leds/led_0' defined in ..\platforms\Seeed Studio\zephyr\boards\arm\xiao_nrf54l15\xiao_nrf54l15_common.dtsi:12 */
		led0: led_0 {
			gpios = < &gpio2 0x0 0x1 >; /* in ..\platforms\Seeed Studio\zephyr\boards\arm\xiao_nrf54l15\xiao_nrf54l15_common.dtsi:13 */
			label = "LED 0";            /* in ..\platforms\Seeed Studio\zephyr\boards\arm\xiao_nrf54l15\xiao_nrf54l15_common.dtsi:14 */
		};
	};

	/* node '/buttons' defined in ..\platforms\Seeed Studio\zephyr\boards\arm\xiao_nrf54l15\xiao_nrf54l15_common.dtsi:18 */
	buttons: buttons {
		compatible = "gpio-keys"; /* in ..\platforms\Seeed Studio\zephyr\boards\arm\xiao_nrf54l15\xiao_nrf54l15_common.dtsi:19 */

		/* node '/buttons/usr-btn' defined in ..\platforms\Seeed Studio\zephyr\boards\arm\xiao_nrf54l15\xiao_nrf54l15_common.dtsi:21 */
		usr_btn: usr-btn {
			gpios = < &gpio0 0x0 0x11 >; /* in ..\platforms\Seeed Studio\zephyr\boards\arm\xiao_nrf54l15\xiao_nrf54l15_common.dtsi:22 */
			label = "USR";               /* in ..\platforms\Seeed Studio\zephyr\boards\arm\xiao_nrf54l15\xiao_nrf54l15_common.dtsi:23 */
			zephyr,code = < 0x1c >;      /* in ..\platforms\Seeed Studio\zephyr\boards\arm\xiao_nrf54l15\xiao_nrf54l15_common.dtsi:24 */
		};
	};

	/* node '/aliases' defined in ..\platforms\Seeed Studio\zephyr\boards\arm\xiao_nrf54l15\xiao_nrf54l15_common.dtsi:28 */
	aliases {
		led0 = &led0;        /* in ..\platforms\Seeed Studio\zephyr\boards\arm\xiao_nrf54l15\xiao_nrf54l15_common.dtsi:29 */
		buttons = &buttons;  /* in ..\platforms\Seeed Studio\zephyr\boards\arm\xiao_nrf54l15\xiao_nrf54l15_common.dtsi:30 */
		dmic20 = &pdm20;     /* in ..\platforms\Seeed Studio\zephyr\boards\arm\xiao_nrf54l15\xiao_nrf54l15_common.dtsi:31 */
		sw0 = &usr_btn;      /* in ..\platforms\Seeed Studio\zephyr\boards\arm\xiao_nrf54l15\xiao_nrf54l15_common.dtsi:32 */
		watchdog0 = &wdt31;  /* in ..\platforms\Seeed Studio\zephyr\boards\arm\xiao_nrf54l15\xiao_nrf54l15_common.dtsi:33 */
		imu0 = &lsm6ds3tr_c; /* in ..\platforms\Seeed Studio\zephyr\boards\arm\xiao_nrf54l15\xiao_nrf54l15_nrf54l15_cpuapp.dts:56 */
	};

	/* node '/pdm-imu-pwr' defined in ..\platforms\Seeed Studio\zephyr\boards\arm\xiao_nrf54l15\xiao_nrf54l15_nrf54l15_cpuapp.dts:15 */
	pdm_imu_pwr: pdm-imu-pwr {
		compatible = "regulator-fixed-sync",
		             "regulator-fixed";      /* in ..\platforms\Seeed Studio\zephyr\boards\arm\xiao_nrf54l15\xiao_nrf54l15_nrf54l15_cpuapp.dts:16 */
		regulator-name = "pdm-imu-pwr";      /* in ..\platforms\Seeed Studio\zephyr\boards\arm\xiao_nrf54l15\xiao_nrf54l15_nrf54l15_cpuapp.dts:17 */
		enable-gpios = < &gpio0 0x1 0x200 >; /* in ..\platforms\Seeed Studio\zephyr\boards\arm\xiao_nrf54l15\xiao_nrf54l15_nrf54l15_cpuapp.dts:18 */
		regulator-boot-on;                   /* in ..\platforms\Seeed Studio\zephyr\boards\arm\xiao_nrf54l15\xiao_nrf54l15_nrf54l15_cpuapp.dts:19 */
		startup-delay-us = < 0xbb8 >;        /* in ..\platforms\Seeed Studio\zephyr\boards\arm\xiao_nrf54l15\xiao_nrf54l15_nrf54l15_cpuapp.dts:20 */
	};

	/* node '/rfsw-ctl' defined in ..\platforms\Seeed Studio\zephyr\boards\arm\xiao_nrf54l15\xiao_nrf54l15_nrf54l15_cpuapp.dts:23 */
	rfsw_ctl: rfsw-ctl {
		compatible = "regulator-fixed";    /* in ..\platforms\Seeed Studio\zephyr\boards\arm\xiao_nrf54l15\xiao_nrf54l15_nrf54l15_cpuapp.dts:24 */
		regulator-name = "rfsw-ctl";       /* in ..\platforms\Seeed Studio\zephyr\boards\arm\xiao_nrf54l15\xiao_nrf54l15_nrf54l15_cpuapp.dts:25 */
		enable-gpios = < &gpio2 0x5 0x1 >; /* in ..\platforms\Seeed Studio\zephyr\boards\arm\xiao_nrf54l15\xiao_nrf54l15_nrf54l15_cpuapp.dts:26 */
		regulator-boot-on;                 /* in ..\platforms\Seeed Studio\zephyr\boards\arm\xiao_nrf54l15\xiao_nrf54l15_nrf54l15_cpuapp.dts:27 */
	};

	/* node '/rfsw-pwr' defined in ..\platforms\Seeed Studio\zephyr\boards\arm\xiao_nrf54l15\xiao_nrf54l15_nrf54l15_cpuapp.dts:30 */
	rfsw_pwr: rfsw-pwr {
		compatible = "regulator-fixed";    /* in ..\platforms\Seeed Studio\zephyr\boards\arm\xiao_nrf54l15\xiao_nrf54l15_nrf54l15_cpuapp.dts:31 */
		regulator-name = "rfsw-pwr";       /* in ..\platforms\Seeed Studio\zephyr\boards\arm\xiao_nrf54l15\xiao_nrf54l15_nrf54l15_cpuapp.dts:32 */
		enable-gpios = < &gpio2 0x3 0x0 >; /* in ..\platforms\Seeed Studio\zephyr\boards\arm\xiao_nrf54l15\xiao_nrf54l15_nrf54l15_cpuapp.dts:33 */
		regulator-boot-on;                 /* in ..\platforms\Seeed Studio\zephyr\boards\arm\xiao_nrf54l15\xiao_nrf54l15_nrf54l15_cpuapp.dts:34 */
	};

	/* node '/vbat-pwr' defined in ..\platforms\Seeed Studio\zephyr\boards\arm\xiao_nrf54l15\xiao_nrf54l15_nrf54l15_cpuapp.dts:37 */
	vbat_pwr: vbat-pwr {
		compatible = "regulator-fixed";    /* in ..\platforms\Seeed Studio\zephyr\boards\arm\xiao_nrf54l15\xiao_nrf54l15_nrf54l15_cpuapp.dts:38 */
		regulator-name = "vbat";           /* in ..\platforms\Seeed Studio\zephyr\boards\arm\xiao_nrf54l15\xiao_nrf54l15_nrf54l15_cpuapp.dts:39 */
		enable-gpios = < &gpio1 0xf 0x0 >; /* in ..\platforms\Seeed Studio\zephyr\boards\arm\xiao_nrf54l15\xiao_nrf54l15_nrf54l15_cpuapp.dts:40 */
		regulator-boot-on;                 /* in ..\platforms\Seeed Studio\zephyr\boards\arm\xiao_nrf54l15\xiao_nrf54l15_nrf54l15_cpuapp.dts:41 */
	};
};
